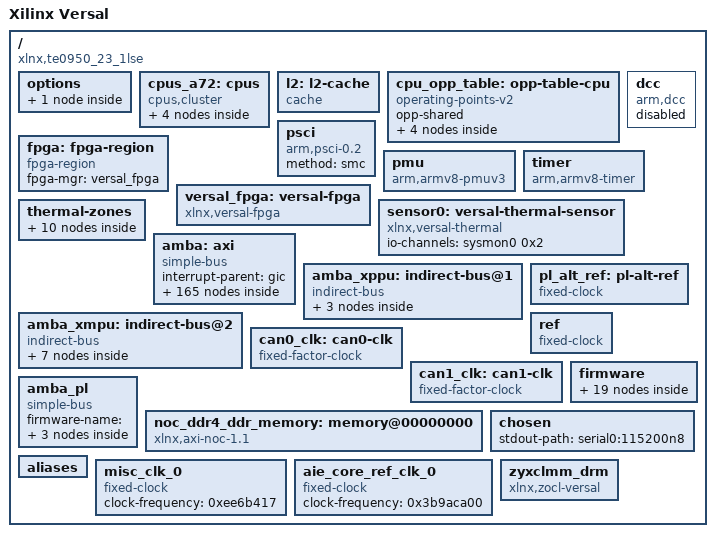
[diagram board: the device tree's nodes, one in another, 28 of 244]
/dts-v1/;
/ {
        compatible = "xlnx,te0950_23_1lse";
        #address-cells = <0x2>;
        #size-cells = <0x2>;
        model = "Xilinx Versal";
        board = "te0950_23_1lse";
        device_id = "xcve2302";
        slrcount = <0x1>;
        family = "Versal";
        speed_grade = "1LP";

        options {

                u-boot {
                        compatible = "u-boot,config";
                        bootscr-address = <0x0 0x20000000>;
                };
        };

        cpus_a72: cpus {
                phandle = <0xb8>;
                #address-cells = <0x1>;
                #size-cells = <0x0>;
                compatible = "cpus,cluster";
                #ranges-address-cells = <0x2>;
                #ranges-size-cells = <0x2>;

                psv_cortexa72_0: cpu@0 {
                        phandle = <0xb9>;
                        compatible = "arm,cortex-a72", "arm,armv8";
                        device_type = "cpu";
                        enable-method = "psci";
                        operating-points-v2 = <&cpu_opp_table>;
                        reg = <0x0>;
                        cpu-idle-states = <&CPU_SLEEP_0>;
                        power-domains = <&versal_firmware 0x18110003>;
                        d-cache-size = <0x8000>;
                        d-cache-line-size = <0x40>;
                        d-cache-sets = <0x100>;
                        i-cache-size = <0xc000>;
                        i-cache-line-size = <0x40>;
                        i-cache-sets = <0x100>;
                        next-level-cache = <&l2>;
                        clocks = <&versal_clk 0x4d>;
                        xlnx,timestamp-clk-freq = <0x5e0afa3>;
                        xlnx,pss-ref-clk-freq = <0x1fca055>;
                        stamp-frequency = <0x5e0afa3>;
                        xlnx,ip-name = "psv_cortexa72";
                        xlnx,cpu-clk-freq-hz = <0x391f0181>;
                        cpu-frequency = <0x391f0181>;
                        bus-handle = <0x1>;
                };

                psv_cortexa72_1: cpu@1 {
                        phandle = <0xba>;
                        compatible = "arm,cortex-a72", "arm,armv8";
                        device_type = "cpu";
                        enable-method = "psci";
                        operating-points-v2 = <&cpu_opp_table>;
                        reg = <0x1>;
                        cpu-idle-states = <&CPU_SLEEP_0>;
                        power-domains = <&versal_firmware 0x18110004>;
                        d-cache-size = <0x8000>;
                        d-cache-line-size = <0x40>;
                        d-cache-sets = <0x100>;
                        i-cache-size = <0xc000>;
                        i-cache-line-size = <0x40>;
                        i-cache-sets = <0x100>;
                        next-level-cache = <&l2>;
                        xlnx,timestamp-clk-freq = <0x5e0afa3>;
                        xlnx,pss-ref-clk-freq = <0x1fca055>;
                        stamp-frequency = <0x5e0afa3>;
                        xlnx,ip-name = "psv_cortexa72";
                        xlnx,cpu-clk-freq-hz = <0x391f0181>;
                        cpu-frequency = <0x391f0181>;
                        bus-handle = <0x1>;
                };

                idle-states {
                        entry-method = "psci";

                        CPU_SLEEP_0: cpu-sleep-0 {
                                phandle = <0x94>;
                                compatible = "arm,idle-state";
                                arm,psci-suspend-param = <0x40000000>;
                                local-timer-stop;
                                entry-latency-us = <0x12c>;
                                exit-latency-us = <0x258>;
                                min-residency-us = <0x2710>;
                        };
                };
        };

        l2: l2-cache {
                phandle = <0x96>;
                compatible = "cache";
                cache-level = <0x2>;
                cache-size = <0x100000>;
                cache-line-size = <0x40>;
                cache-sets = <0x1000>;
                cache-unified;
        };

        cpu_opp_table: opp-table-cpu {
                phandle = <0x93>;
                compatible = "operating-points-v2";
                opp-shared;

                opp-959000000 {
                        opp-hz = <0x0 0x39292dc0>;
                        clock-latency-ns = <0x7a120>;
                        opp-microvolt = <0xf4240>;
                };

                opp-479500000 {
                        opp-hz = <0x0 0x1c9496e0>;
                        clock-latency-ns = <0x7a120>;
                        opp-microvolt = <0xf4240>;
                };

                opp-319666667 {
                        opp-hz = <0x0 0x130db9eb>;
                        clock-latency-ns = <0x7a120>;
                        opp-microvolt = <0xf4240>;
                };

                opp-239750000 {
                        opp-hz = <0x0 0xe4a4b70>;
                        clock-latency-ns = <0x7a120>;
                        opp-microvolt = <0xf4240>;
                };
        };

        dcc: dcc {
                phandle = <0xc3>;
                compatible = "arm,dcc";
                status = "disabled";
                bootph-all;
        };

        fpga: fpga-region {
                phandle = <0xc4>;
                compatible = "fpga-region";
                fpga-mgr = <&versal_fpga>;
                #address-cells = <0x2>;
                #size-cells = <0x2>;
        };

        psci: psci {
                phandle = <0xc5>;
                compatible = "arm,psci-0.2";
                method = "smc";
        };

        pmu {
                compatible = "arm,armv8-pmuv3";
                interrupt-parent = <&gic>;
                interrupts = <0x1 0x7 0x304>;
        };

        timer: timer {
                phandle = <0xc6>;
                compatible = "arm,armv8-timer";
                interrupt-parent = <&gic>;
                interrupts = <0x1 0xd 0x4 0x1 0xe 0x4 0x1 0xb 0x4 0x1 0xa 0x4>;
        };

        versal_fpga: versal-fpga {
                phandle = <0xac>;
                compatible = "xlnx,versal-fpga";
        };

        sensor0: versal-thermal-sensor {
                phandle = <0xae>;
                compatible = "xlnx,versal-thermal";
                #thermal-sensor-cells = <0x1>;
                io-channels = <&sysmon0 0x2>;
                io-channel-names = "sysmon-temp-channel";
        };

        thermal-zones {

                versal_thermal: versal-thermal {
                        phandle = <0xc7>;
                        polling-delay-passive = <0xfa>;
                        polling-delay = <0x3e8>;
                        thermal-sensors = <&sensor0 0x0>;

                        trips {

                                temp_alert: temp-alert {
                                        phandle = <0xc8>;
                                        temperature = <0x11170>;
                                        hysteresis = <0x0>;
                                        type = "passive";
                                };

                                ot_crit: ot-crit {
                                        phandle = <0xc9>;
                                        temperature = <0x1e848>;
                                        hysteresis = <0x0>;
                                        type = "critical";
                                };
                        };

                        cooling-maps {
                        };
                };

                versal_thermal_aie: versal-aie-thermal {
                        phandle = <0xca>;
                        polling-delay-passive = <0xfa>;
                        polling-delay = <0x3e8>;
                        thermal-sensors = <&sensor0 0x1>;

                        trips {

                                temp_alert_aie: temp-alert-aie {
                                        phandle = <0xcb>;
                                        temperature = <0x11170>;
                                        hysteresis = <0x0>;
                                        type = "passive";
                                };

                                ot_crit_aie: ot-crit-aie {
                                        phandle = <0xcc>;
                                        temperature = <0x1e848>;
                                        hysteresis = <0x0>;
                                        type = "critical";
                                };
                        };

                        cooling-maps {
                        };
                };
        };

        amba: axi {
                phandle = <0x1>;
                compatible = "simple-bus";
                #address-cells = <0x2>;
                #size-cells = <0x2>;
                ranges;
                interrupt-parent = <&gic>;
                bootph-all;

                can0: can@ff060000 {
                        phandle = <0xcd>;
                        compatible = "xlnx,canfd-2.0";
                        status = "disabled";
                        reg = <0x0 0xff060000 0x0 0x6000>;
                        interrupts = <0x0 0x14 0x4>;
                        interrupt-parent = <&gic>;
                        clock-names = "can_clk", "s_axi_aclk";
                        rx-fifo-depth = <0x40>;
                        tx-mailbox-count = <0x20>;
                        clocks = <&can0_clk>,
                         <&versal_clk 0x52>;
                        power-domains = <&versal_firmware 0x1822401f>;
                };

                can1: can@ff070000 {
                        phandle = <0xce>;
                        compatible = "xlnx,canfd-2.0";
                        status = "disabled";
                        reg = <0x0 0xff070000 0x0 0x6000>;
                        interrupts = <0x0 0x15 0x4>;
                        interrupt-parent = <&gic>;
                        clock-names = "can_clk", "s_axi_aclk";
                        rx-fifo-depth = <0x40>;
                        tx-mailbox-count = <0x20>;
                        clocks = <&can1_clk>,
                         <&versal_clk 0x52>;
                        power-domains = <&versal_firmware 0x18224020>;
                };

                cci: cci@fd000000 {
                        phandle = <0x5d>;
                        compatible = "arm,cci-500";
                        status = "okay";
                        reg = <0x0 0xfd000000 0x0 0x10000>;
                        ranges = <0x0 0x0 0xfd000000 0xa0000>;
                        #address-cells = <0x1>;
                        #size-cells = <0x1>;
                        xlnx,ip-name = "psv_fpd_maincci";

                        cci_pmu: pmu@10000 {
                                phandle = <0xcf>;
                                compatible = "arm,cci-500-pmu,r0";
                                reg = <0x10000 0x90000>;
                                interrupt-parent = <&gic>;
                                interrupts = <0x0 0x6a 0x4 0x0 0x6a 0x4 0x0 0x6a 0x4 0x0 0x6a 0x4 0x0 0x6a 0x4 0x0 0x6a 0x4 0x0 0x6a 0x4 0x0 0x6a 0x4>;
                        };
                };

                lpd_dma_chan0: dma-controller@ffa80000 {
                        phandle = <0x86>;
                        compatible = "xlnx,zynqmp-dma-1.0";
                        status = "okay";
                        reg = <0x0 0xffa80000 0x0 0x1000>;
                        interrupts = <0x0 0x3c 0x4>;
                        interrupt-parent = <&gic>;
                        clock-names = "clk_main", "clk_apb";
                        xlnx,dma-type = <0x1>;
                        #dma-cells = <0x1>;
                        xlnx,bus-width = <0x40>;
                        clocks = <&versal_clk 0x51>,
                         <&versal_clk 0x52>;
                        power-domains = <&versal_firmware 0x18224035>;
                        xlnx,is-cache-coherent = <0x0>;
                        xlnx,ip-name = "psv_adma";
                        xlnx,dma-mode = <0x1>;
                };

                lpd_dma_chan1: dma-controller@ffa90000 {
                        phandle = <0x87>;
                        compatible = "xlnx,zynqmp-dma-1.0";
                        status = "okay";
                        reg = <0x0 0xffa90000 0x0 0x1000>;
                        interrupts = <0x0 0x3d 0x4>;
                        interrupt-parent = <&gic>;
                        clock-names = "clk_main", "clk_apb";
                        xlnx,dma-type = <0x1>;
                        #dma-cells = <0x1>;
                        xlnx,bus-width = <0x40>;
                        clocks = <&versal_clk 0x51>,
                         <&versal_clk 0x52>;
                        power-domains = <&versal_firmware 0x18224036>;
                        xlnx,is-cache-coherent = <0x0>;
                        xlnx,ip-name = "psv_adma";
                        xlnx,dma-mode = <0x1>;
                };

                lpd_dma_chan2: dma-controller@ffaa0000 {
                        phandle = <0x88>;
                        compatible = "xlnx,zynqmp-dma-1.0";
                        status = "okay";
                        reg = <0x0 0xffaa0000 0x0 0x1000>;
                        interrupts = <0x0 0x3e 0x4>;
                        interrupt-parent = <&gic>;
                        clock-names = "clk_main", "clk_apb";
                        xlnx,dma-type = <0x1>;
                        #dma-cells = <0x1>;
                        xlnx,bus-width = <0x40>;
                        clocks = <&versal_clk 0x51>,
                         <&versal_clk 0x52>;
                        power-domains = <&versal_firmware 0x18224037>;
                        xlnx,is-cache-coherent = <0x0>;
                        xlnx,ip-name = "psv_adma";
                        xlnx,dma-mode = <0x1>;
                };

                lpd_dma_chan3: dma-controller@ffab0000 {
                        phandle = <0x89>;
                        compatible = "xlnx,zynqmp-dma-1.0";
                        status = "okay";
                        reg = <0x0 0xffab0000 0x0 0x1000>;
                        interrupts = <0x0 0x3f 0x4>;
                        interrupt-parent = <&gic>;
                        clock-names = "clk_main", "clk_apb";
                        xlnx,dma-type = <0x1>;
                        #dma-cells = <0x1>;
                        xlnx,bus-width = <0x40>;
                        clocks = <&versal_clk 0x51>,
                         <&versal_clk 0x52>;
                        power-domains = <&versal_firmware 0x18224038>;
                        xlnx,is-cache-coherent = <0x0>;
                        xlnx,ip-name = "psv_adma";
                        xlnx,dma-mode = <0x1>;
                };

                lpd_dma_chan4: dma-controller@ffac0000 {
                        phandle = <0x8a>;
                        compatible = "xlnx,zynqmp-dma-1.0";
                        status = "okay";
                        reg = <0x0 0xffac0000 0x0 0x1000>;
                        interrupts = <0x0 0x40 0x4>;
                        interrupt-parent = <&gic>;
                        clock-names = "clk_main", "clk_apb";
                        xlnx,dma-type = <0x1>;
                        #dma-cells = <0x1>;
                        xlnx,bus-width = <0x40>;
                        clocks = <&versal_clk 0x51>,
                         <&versal_clk 0x52>;
                        power-domains = <&versal_firmware 0x18224039>;
                        xlnx,is-cache-coherent = <0x0>;
                        xlnx,ip-name = "psv_adma";
                        xlnx,dma-mode = <0x1>;
                };

                lpd_dma_chan5: dma-controller@ffad0000 {
                        phandle = <0x8b>;
                        compatible = "xlnx,zynqmp-dma-1.0";
                        status = "okay";
                        reg = <0x0 0xffad0000 0x0 0x1000>;
                        interrupts = <0x0 0x41 0x4>;
                        interrupt-parent = <&gic>;
                        clock-names = "clk_main", "clk_apb";
                        xlnx,dma-type = <0x1>;
                        #dma-cells = <0x1>;
                        xlnx,bus-width = <0x40>;
                        clocks = <&versal_clk 0x51>,
                         <&versal_clk 0x52>;
                        power-domains = <&versal_firmware 0x1822403a>;
                        xlnx,is-cache-coherent = <0x0>;
                        xlnx,ip-name = "psv_adma";
                        xlnx,dma-mode = <0x1>;
                };

                lpd_dma_chan6: dma-controller@ffae0000 {
                        phandle = <0x8c>;
                        compatible = "xlnx,zynqmp-dma-1.0";
                        status = "okay";
                        reg = <0x0 0xffae0000 0x0 0x1000>;
                        interrupts = <0x0 0x42 0x4>;
                        interrupt-parent = <&gic>;
                        clock-names = "clk_main", "clk_apb";
                        xlnx,dma-type = <0x1>;
                        #dma-cells = <0x1>;
                        xlnx,bus-width = <0x40>;
                        clocks = <&versal_clk 0x51>,
                         <&versal_clk 0x52>;
                        power-domains = <&versal_firmware 0x1822403b>;
                        xlnx,is-cache-coherent = <0x0>;
                        xlnx,ip-name = "psv_adma";
                        xlnx,dma-mode = <0x1>;
                };

                lpd_dma_chan7: dma-controller@ffaf0000 {
                        phandle = <0x8d>;
                        compatible = "xlnx,zynqmp-dma-1.0";
                        status = "okay";
                        reg = <0x0 0xffaf0000 0x0 0x1000>;
                        interrupts = <0x0 0x43 0x4>;
                        interrupt-parent = <&gic>;
                        clock-names = "clk_main", "clk_apb";
                        xlnx,dma-type = <0x1>;
                        #dma-cells = <0x1>;
                        xlnx,bus-width = <0x40>;
                        clocks = <&versal_clk 0x51>,
                         <&versal_clk 0x52>;
                        power-domains = <&versal_firmware 0x1822403c>;
                        xlnx,is-cache-coherent = <0x0>;
                        xlnx,ip-name = "psv_adma";
                        xlnx,dma-mode = <0x1>;
                };

                gem0: ethernet@ff0c0000 {
                        phandle = <0x6f>;
                        compatible = "xlnx,versal-gem", "cdns,gem";
                        status = "okay";
                        reg = <0x0 0xff0c0000 0x0 0x1000>;
                        interrupts = <0x0 0x38 0x4 0x0 0x38 0x4>;
                        interrupt-parent = <&gic>;
                        clock-names = "pclk", "hclk", "tx_clk", "rx_clk", "tsu_clk";
                        #address-cells = <0x1>;
                        #size-cells = <0x0>;
                        clocks = <&versal_clk 0x52>,
                         <&versal_clk 0x58>,
                         <&versal_clk 0x31>,
                         <&versal_clk 0x30>,
                         <&versal_clk 0x2b>;
                        power-domains = <&versal_firmware 0x18224019>;
                        xlnx,has-mdio = <0x1>;
                        xlnx,is-cache-coherent = <0x0>;
                        xlnx,gem-board-interface = "custom";
                        phy-mode = "rgmii-id";
                        xlnx,enet-slcr-1000mbps-div0 = <0x7>;
                        xlnx,enet-slcr-10mbps-div0 = <0x15e>;
                        xlnx,enet-tsu-clk-freq-hz = <0xe47c060>;
                        xlnx,ip-name = "psv_ethernet";
                        xlnx,eth-mode = <0x1>;
                        xlnx,enet-clk-freq-hz = <0x7735938>;
                        xlnx,enet-slcr-100mbps-div0 = <0x23>;
                };

                gem1: ethernet@ff0d0000 {
                        phandle = <0xd0>;
                        compatible = "xlnx,versal-gem", "cdns,gem";
                        status = "disabled";
                        reg = <0x0 0xff0d0000 0x0 0x1000>;
                        interrupts = <0x0 0x3a 0x4 0x0 0x3a 0x4>;
                        interrupt-parent = <&gic>;
                        clock-names = "pclk", "hclk", "tx_clk", "rx_clk", "tsu_clk";
                        #address-cells = <0x1>;
                        #size-cells = <0x0>;
                        clocks = <&versal_clk 0x52>,
                         <&versal_clk 0x59>,
                         <&versal_clk 0x33>,
                         <&versal_clk 0x32>,
                         <&versal_clk 0x2b>;
                        power-domains = <&versal_firmware 0x1822401a>;
                };

                gpio0: gpio@ff0b0000 {
                        phandle = <0x6e>;
                        compatible = "xlnx,versal-gpio-1.0";
                        status = "okay";
                        reg = <0x0 0xff0b0000 0x0 0x1000>;
                        interrupts = <0x0 0xd 0x4>;
                        interrupt-parent = <&gic>;
                        #gpio-cells = <0x2>;
                        gpio-controller;
                        #interrupt-cells = <0x2>;
                        interrupt-controller;
                        clocks = <&versal_clk 0x52>;
                        power-domains = <&versal_firmware 0x18224023>;
                        xlnx,ip-name = "psv_gpio";
                        emio-gpio-width = "";
                        gpio-line-names = "", "", "", "", "", "", "", "", "", "", "", "", "", "", "", "", "", "", "", "", "", "", "LPD_MIO22", "";
                };

                gpio1: gpio@f1020000 {
                        phandle = <0x31>;
                        compatible = "xlnx,pmc-gpio-1.0";
                        status = "okay";
                        reg = <0x0 0xf1020000 0x0 0x1000>;
                        interrupts = <0x0 0x7a 0x4>;
                        interrupt-parent = <&gic>;
                        #gpio-cells = <0x2>;
                        gpio-controller;
                        #interrupt-cells = <0x2>;
                        interrupt-controller;
                        clocks = <&versal_clk 0x3d>;
                        power-domains = <&versal_firmware 0x1822402c>;
                        xlnx,ip-name = "psv_pmc_gpio";
                        gpio-line-names = "", "", "", "", "", "", "", "", "", "", "", "", "", "", "", "", "", "", "", "", "", "", "", "", "", "", "", "PMC_MIO27", "", "", "", "", "", "", "", "", "", "USB_OC", "", "", "", "", "", "", "", "", "", "", "", "", "", "LED0", "", "", "", "", "", "", "", "";
                };

                i2c0: i2c@ff020000 {
                        phandle = <0xd1>;
                        compatible = "cdns,i2c-r1p14";
                        status = "disabled";
                        reg = <0x0 0xff020000 0x0 0x1000>;
                        interrupts = <0x0 0xe 0x4>;
                        interrupt-parent = <&gic>;
                        clock-frequency = <0x186a0>;
                        #address-cells = <0x1>;
                        #size-cells = <0x0>;
                        clocks = <&versal_clk 0x62>;
                        power-domains = <&versal_firmware 0x1822401d>;

                        i2cswitch@70 {
                                compatible = "nxp,pca9548";
                                #address-cells = <0x1>;
                                #size-cells = <0x0>;
                                reg = <0x70>;
                                i2c-mux-idle-disconnect;

                                i2c_cruvi_hs1: i2c@0 {
                                        phandle = <0xd2>;
                                        reg = <0x0>;
                                };

                                i2c_cruvi_hs2: i2c@1 {
                                        phandle = <0xd3>;
                                        reg = <0x1>;
                                };

                                i2c_qsfp: i2c@2 {
                                        phandle = <0xd4>;
                                        reg = <0x2>;
                                };

                                i2c_fmc: i2c@3 {
                                        phandle = <0xd5>;
                                        reg = <0x3>;
                                };
                        };
                };

                i2c1: i2c@ff030000 {
                        phandle = <0x6b>;
                        compatible = "cdns,i2c-r1p14";
                        status = "okay";
                        reg = <0x0 0xff030000 0x0 0x1000>;
                        interrupts = <0x0 0xf 0x4>;
                        interrupt-parent = <&gic>;
                        clock-frequency = <0x186a0>;
                        #address-cells = <0x1>;
                        #size-cells = <0x0>;
                        clocks = <&versal_clk 0x63>;
                        power-domains = <&versal_firmware 0x1822401e>;
                        xlnx,clock-freq = <0x5e0afa3>;
                        xlnx,i2c-clk-freq-hz = <0x5e0afa3>;
                        xlnx,ip-name = "psv_i2c";
                        xlnx,iic-board-interface = "custom";
                };

                i2c2: i2c@f1000000 {
                        phandle = <0x2f>;
                        compatible = "cdns,i2c-r1p14";
                        status = "okay";
                        reg = <0x0 0xf1000000 0x0 0x1000>;
                        interrupts = <0x0 0x7b 0x4>;
                        interrupt-parent = <&gic>;
                        clock-frequency = <0x186a0>;
                        #address-cells = <0x1>;
                        #size-cells = <0x0>;
                        clocks = <&versal_clk 0x3e>;
                        power-domains = <&versal_firmware 0x1822402d>;
                        xlnx,clock-freq = <0x5e0afa3>;
                        xlnx,i2c-clk-freq-hz = <0x5e0afa3>;
                        xlnx,ip-name = "psv_pmc_i2c";

                        eeprom: eeprom@50 {
                                phandle = <0xd6>;
                                compatible = "microchip,24aa025", "atmel,24c02";
                                reg = <0x50>;
                                #address-cells = <0x1>;
                                #size-cells = <0x1>;

                                eth0_addr: eth-mac-addr@FA {
                                        phandle = <0xd7>;
                                        reg = <0xfa 0x6>;
                                };
                        };
                };

                mc0: memory-controller@f6150000 {
                        phandle = <0xd8>;
                        compatible = "xlnx,versal-ddrmc";
                        status = "disabled";
                        reg = <0x0 0xf6150000 0x0 0x2000 0x0 0xf6070000 0x0 0x20000>;
                        reg-names = "base", "noc";
                        interrupts = <0x0 0x93 0x4>;
                        interrupt-parent = <&gic>;
                };

                mc1: memory-controller@f62c0000 {
                        phandle = <0xd9>;
                        compatible = "xlnx,versal-ddrmc";
                        status = "disabled";
                        reg = <0x0 0xf62c0000 0x0 0x2000 0x0 0xf6210000 0x0 0x20000>;
                        reg-names = "base", "noc";
                        interrupts = <0x0 0x93 0x4>;
                        interrupt-parent = <&gic>;
                };

                mc2: memory-controller@f6430000 {
                        phandle = <0xda>;
                        compatible = "xlnx,versal-ddrmc";
                        status = "disabled";
                        reg = <0x0 0xf6430000 0x0 0x2000 0x0 0xf6380000 0x0 0x20000>;
                        reg-names = "base", "noc";
                        interrupts = <0x0 0x93 0x4>;
                        interrupt-parent = <&gic>;
                };

                mc3: memory-controller@f65a0000 {
                        phandle = <0xdb>;
                        compatible = "xlnx,versal-ddrmc";
                        status = "disabled";
                        reg = <0x0 0xf65a0000 0x0 0x2000 0x0 0xf64f0000 0x0 0x20000>;
                        reg-names = "base", "noc";
                        interrupts = <0x0 0x93 0x4>;
                        interrupt-parent = <&gic>;
                };

                ocm: memory-controller@ff960000 {
                        phandle = <0xdc>;
                        compatible = "xlnx,zynqmp-ocmc-1.0";
                        reg = <0x0 0xff960000 0x0 0x1000>;
                        interrupts = <0x0 0xa 0x4>;
                        interrupt-parent = <&gic>;
                };

                rtc: rtc@f12a0000 {
                        phandle = <0x44>;
                        compatible = "xlnx,zynqmp-rtc";
                        status = "okay";
                        reg = <0x0 0xf12a0000 0x0 0x100>;
                        interrupt-names = "alarm", "sec";
                        interrupts = <0x0 0x8e 0x4 0x0 0x8f 0x4>;
                        interrupt-parent = <&gic>;
                        calibration = <0x7fff>;
                        power-domains = <&versal_firmware 0x18224034>;
                        xlnx,ip-name = "psv_pmc_rtc";
                };

                sdhci0: mmc@f1040000 {
                        phandle = <0x32>;
                        compatible = "xlnx,versal-8.9a", "arasan,sdhci-8.9a";
                        status = "okay";
                        reg = <0x0 0xf1040000 0x0 0x10000>;
                        interrupts = <0x0 0x7e 0x4>;
                        interrupt-parent = <&gic>;
                        clock-names = "clk_xin", "clk_ahb", "gate";
                        #clock-cells = <0x1>;
                        clock-output-names = "clk_out_sd0", "clk_in_sd0";
                        clocks = <&versal_clk 0x3b>,
                         <&versal_clk 0x52>,
                         <&versal_clk 0x4a>;
                        power-domains = <&versal_firmware 0x1822402e>;
                        xlnx,sd-board-interface = "custom";
                        xlnx,is-cache-coherent = <0x0>;
                        xlnx,clk-50-ddr-otap-dly = <0x5>;
                        xlnx,clk-50-sdr-itap-dly = <0x2c>;
                        xlnx,has-emio = <0x0>;
                        clock-frequency = <0xbc15f46>;
                        xlnx,clk-100-sdr-otap-dly = <0x0>;
                        xlnx,mio-bank = <0x1>;
                        xlnx,ip-name = "psv_pmc_sd";
                        xlnx,bus-width = <0x8>;
                        xlnx,card-detect = <0x0>;
                        xlnx,has-wp = <0x0>;
                        xlnx,has-cd = <0x0>;
                        xlnx,slot-type = <0x1>;
                        xlnx,clk-50-sdr-otap-dly = <0x5>;
                        xlnx,clk-50-ddr-itap-dly = <0x1e>;
                        xlnx,has-power = <0x0>;
                        xlnx,clk-200-sdr-otap-dly = <0x2>;
                        xlnx,sdio-clk-freq-hz = <0xbc15f46>;
                        xlnx,write-protect = <0x0>;
                        bus-width = <0x8>;
                };

                sdhci1: mmc@f1050000 {
                        phandle = <0x33>;
                        compatible = "xlnx,versal-8.9a", "arasan,sdhci-8.9a";
                        status = "okay";
                        reg = <0x0 0xf1050000 0x0 0x10000>;
                        interrupts = <0x0 0x80 0x4>;
                        interrupt-parent = <&gic>;
                        clock-names = "clk_xin", "clk_ahb", "gate";
                        #clock-cells = <0x1>;
                        clock-output-names = "clk_out_sd1", "clk_in_sd1";
                        clocks = <&versal_clk 0x3c>,
                         <&versal_clk 0x52>,
                         <&versal_clk 0x4a>;
                        power-domains = <&versal_firmware 0x1822402f>;
                        xlnx,sd-board-interface = "custom";
                        xlnx,is-cache-coherent = <0x0>;
                        xlnx,clk-50-ddr-otap-dly = <0x0>;
                        xlnx,clk-50-sdr-itap-dly = <0x2c>;
                        xlnx,has-emio = <0x0>;
                        clock-frequency = <0xbc15f46>;
                        xlnx,clk-100-sdr-otap-dly = <0x0>;
                        xlnx,mio-bank = <0x1>;
                        xlnx,ip-name = "psv_pmc_sd";
                        xlnx,bus-width = <0x4>;
                        xlnx,card-detect = <0x1>;
                        xlnx,has-wp = <0x0>;
                        xlnx,has-cd = <0x1>;
                        xlnx,slot-type = <0x2>;
                        xlnx,clk-50-sdr-otap-dly = <0x4>;
                        xlnx,clk-50-ddr-itap-dly = <0x0>;
                        xlnx,has-power = <0x0>;
                        xlnx,clk-200-sdr-otap-dly = <0x0>;
                        xlnx,sdio-clk-freq-hz = <0xbc15f46>;
                        xlnx,write-protect = <0x0>;
                        no-1-8-v;
                };

                serial0: serial@ff000000 {
                        phandle = <0xdd>;
                        compatible = "arm,pl011", "arm,primecell";
                        status = "disabled";
                        reg = <0x0 0xff000000 0x0 0x1000>;
                        interrupts = <0x0 0x12 0x4>;
                        interrupt-parent = <&gic>;
                        reg-io-width = <0x4>;
                        clock-names = "uartclk", "apb_pclk";
                        bootph-all;
                        clocks = <&versal_clk 0x5c>,
                         <&versal_clk 0x52>;
                        power-domains = <&versal_firmware 0x18224021>;
                };

                serial1: serial@ff010000 {
                        phandle = <0x6a>;
                        compatible = "arm,pl011", "arm,primecell";
                        status = "okay";
                        reg = <0x0 0xff010000 0x0 0x1000>;
                        interrupts = <0x0 0x13 0x4>;
                        interrupt-parent = <&gic>;
                        reg-io-width = <0x4>;
                        clock-names = "uartclk", "apb_pclk";
                        bootph-all;
                        clocks = <&versal_clk 0x5d>,
                         <&versal_clk 0x52>;
                        power-domains = <&versal_firmware 0x18224022>;
                        xlnx,clock-freq = <0x5e0afa3>;
                        u-boot,dm-pre-reloc;
                        xlnx,uart-board-interface = "custom";
                        xlnx,has-modem = <0x0>;
                        xlnx,ip-name = "psv_sbsauart";
                        xlnx,baudrate = <0x1c200>;
                        cts-override;
                        port-number = <0x0>;
                        xlnx,uart-clk-freq-hz = <0x5e0afa3>;
                };

                smmu: iommu@fd800000 {
                        phandle = <0x68>;
                        compatible = "arm,mmu-500";
                        status = "okay";
                        reg = <0x0 0xfd800000 0x0 0x40000>;
                        stream-match-mask = <0x7c00>;
                        #iommu-cells = <0x1>;
                        #global-interrupts = <0x1>;
                        interrupts = <0x0 0x6b 0x4 0x0 0x6b 0x4 0x0 0x6b 0x4 0x0 0x6b 0x4 0x0 0x6b 0x4 0x0 0x6b 0x4 0x0 0x6b 0x4 0x0 0x6b 0x4 0x0 0x6b 0x4 0x0 0x6b 0x4 0x0 0x6b 0x4 0x0 0x6b 0x4 0x0 0x6b 0x4 0x0 0x6b 0x4 0x0 0x6b 0x4 0x0 0x6b 0x4 0x0 0x6b 0x4 0x0 0x6b 0x4 0x0 0x6b 0x4 0x0 0x6b 0x4 0x0 0x6b 0x4 0x0 0x6b 0x4 0x0 0x6b 0x4 0x0 0x6b 0x4 0x0 0x6b 0x4 0x0 0x6b 0x4 0x0 0x6b 0x4 0x0 0x6b 0x4 0x0 0x6b 0x4 0x0 0x6b 0x4 0x0 0x6b 0x4 0x0 0x6b 0x4 0x0 0x6b 0x4>;
                        interrupt-parent = <&gic>;
                        xlnx,ip-name = "psv_fpd_smmutcu";
                };

                ospi: spi@f1010000 {
                        phandle = <0x30>;
                        compatible = "xlnx,versal-ospi-1.0", "cdns,qspi-nor";
                        status = "okay";
                        reg = <0x0 0xf1010000 0x0 0x10000 0x0 0xc0000000 0x0 0x20000000>;
                        interrupts = <0x0 0x7c 0x4>;
                        interrupt-parent = <&gic>;
                        cdns,fifo-depth = <0x100>;
                        cdns,fifo-width = <0x4>;
                        cdns,is-dma = <0x1>;
                        cdns,trigger-address = <0xc0000000>;
                        #address-cells = <0x1>;
                        #size-cells = <0x0>;
                        clocks = <&versal_clk 0x3a>;
                        power-domains = <&versal_firmware 0x1822402a>;
                        reset-names = "qspi";
                        resets = <&versal_reset 0xc10402e>;
                        is-stacked = <0x0>;
                        xlnx,is-cache-coherent = <0x0>;
                        xlnx,clock-freq = <0xbc15f46>;
                        xlnx,ip-name = "psv_pmc_ospi";
                        xlnx,ospi-clk-freq-hz = <0xbc15f46>;
                        is-dual = <0x0>;
                        xlnx,ospi-mode = <0x0>;
                };

                qspi: spi@f1030000 {
                        phandle = <0xde>;
                        compatible = "xlnx,versal-qspi-1.0";
                        status = "disabled";
                        reg = <0x0 0xf1030000 0x0 0x1000>;
                        interrupts = <0x0 0x7d 0x4>;
                        interrupt-parent = <&gic>;
                        clock-names = "ref_clk", "pclk";
                        #address-cells = <0x1>;
                        #size-cells = <0x0>;
                        clocks = <&versal_clk 0x39>,
                         <&versal_clk 0x52>;
                        power-domains = <&versal_firmware 0x1822402b>;
                        num-cs = <0x2>;

                        flash@0 {
                                compatible = "jedec,spi-nor";
                                reg = <0x0 0x1>;
                                parallel-memories = <0x0 0x8000000 0x0 0x8000000>;
                                spi-rx-bus-width = <0x4>;
                                spi-tx-bus-width = <0x4>;
                                spi-max-frequency = <0x2625a00>;
                                #address-cells = <0x1>;
                                #size-cells = <0x1>;
                        };
                };

                spi0: spi@ff040000 {
                        phandle = <0xdf>;
                        compatible = "cdns,spi-r1p6";
                        status = "disabled";
                        reg = <0x0 0xff040000 0x0 0x1000>;
                        interrupts = <0x0 0x10 0x4>;
                        interrupt-parent = <&gic>;
                        clock-names = "ref_clk", "pclk";
                        #address-cells = <0x1>;
                        #size-cells = <0x0>;
                        clocks = <&versal_clk 0x5e>,
                         <&versal_clk 0x52>;
                        power-domains = <&versal_firmware 0x1822401b>;
                };

                spi1: spi@ff050000 {
                        phandle = <0xe0>;
                        compatible = "cdns,spi-r1p6";
                        status = "disabled";
                        reg = <0x0 0xff050000 0x0 0x1000>;
                        interrupts = <0x0 0x11 0x4>;
                        interrupt-parent = <&gic>;
                        clock-names = "ref_clk", "pclk";
                        #address-cells = <0x1>;
                        #size-cells = <0x0>;
                        clocks = <&versal_clk 0x5f>,
                         <&versal_clk 0x52>;
                        power-domains = <&versal_firmware 0x1822401c>;
                };

                sysmon0: sysmon@f1270000 {
                        phandle = <0x43>;
                        compatible = "xlnx,versal-sysmon";
                        #io-channel-cells = <0x1>;
                        reg = <0x0 0xf1270000 0x0 0x4000>;
                        interrupts = <0x0 0x90 0x4>;
                        xlnx,numchannels = [02];
                        #address-cells = <0x2>;
                        #size-cells = <0x2>;
                        xlnx,nodeid = <0x18224055>;
                        xlnx,sat-1-desc = "PMC , system , ADC";
                        xlnx,sat-63-desc = "PS , FPD , satellite";
                        xlnx,sat-9-x = <0xae2>;
                        xlnx,sat-9-y = <0x2905>;
                        xlnx,meas-0-root-id = <0x0>;
                        xlnx,meas-1-root-id = <0x1>;
                        xlnx,ip-name = "psv_pmc_sysmon";
                        xlnx,sat-9-desc = "ME , satellite";
                        xlnx,sat-10-x = <0x319>;
                        xlnx,sat-10-y = <0x2905>;
                        xlnx,sat-2-x = <0x23>;
                        xlnx,sat-64-x = <0x23>;
                        xlnx,sat-13-desc = "Clocking , column , satellite";
                        xlnx,sat-2-y = <0xb34>;
                        xlnx,sat-64-y = <0xb34>;
                        xlnx,meas-0-aux-io-n = "LPD_MIO21_502";
                        xlnx,sat-6-desc = "VNOC , satellite";
                        xlnx,meas-0-aux-io-p = "LPD_MIO20_502";
                        xlnx,sat-6-x = <0x1a37>;
                        xlnx,sat-6-y = <0x19f9>;
                        xlnx,sat-10-desc = "ME , satellite";
                        xlnx,sat-3-desc = "XPIO , satellite";
                        xlnx,meas-1-aux-io-n = "LPD_MIO15_502";
                        xlnx,meas-0-slr-number = <0x0>;
                        xlnx,meas-1-aux-io-p = "LPD_MIO14_502";
                        xlnx,sat-11-x = <0xa0e>;
                        xlnx,sat-11-y = <0x23fc>;
                        xlnx,sat-3-x = <0x116a>;
                        status = "okay";
                        xlnx,sat-3-y = <0x5ff>;
                        xlnx,sat-8-desc = "ME , satellite";
                        xlnx,sat-7-x = <0x1a74>;
                        xlnx,sat-7-y = <0x2905>;
                        xlnx,sat-12-desc = "Clocking , column , satellite";
                        xlnx,sat-5-desc = "VNOC , satellite";
                        xlnx,sat-2-desc = "PMC , user , ADC";
                        xlnx,sat-64-desc = "PS , LPD , satellite";
                        xlnx,sat-12-x = <0xa0e>;
                        xlnx,sat-12-y = <0x1dc4>;
                        xlnx,sat-4-x = <0x1d4c>;
                        xlnx,sat-4-y = <0x5ff>;
                        xlnx,meas-1-slr-number = <0x0>;
                        xlnx,sat-8-x = <0x12ab>;
                        xlnx,sat-8-y = <0x2905>;
                        xlnx,meas-0 = "VAUX_CH0";
                        xlnx,meas-1 = "VAUX_CH1";
                        xlnx,sat-7-desc = "ME , satellite";
                        xlnx,sat-11-desc = "Clocking , column , satellite";
                        xlnx,sat-1-x = <0x23>;
                        xlnx,sat-63-x = <0x23>;
                        xlnx,sat-1-y = <0xb34>;
                        xlnx,sat-63-y = <0xb34>;
                        xlnx,sat-4-desc = "XPIO , satellite";
                        xlnx,sat-13-x = <0xa0e>;
                        xlnx,sat-13-y = <0x1795>;
                        xlnx,sat-5-x = <0x1a37>;
                        xlnx,sat-5-y = <0xe06>;

                        supply@0 {
                                reg = <0x0>;
                                xlnx,name = "vaux_ch0";
                        };

                        supply@1 {
                                reg = <0x1>;
                                xlnx,name = "vaux_ch1";
                        };
                };

                sysmon1: sysmon@109270000 {
                        phandle = <0xe1>;
                        compatible = "xlnx,versal-sysmon";
                        status = "disabled";
                        reg = <0x1 0x9270000 0x0 0x4000>;
                        xlnx,numchannels = [00];
                        #address-cells = <0x1>;
                        #size-cells = <0x0>;
                        xlnx,nodeid = <0x18225055>;
                };

                sysmon2: sysmon@111270000 {
                        phandle = <0xe2>;
                        compatible = "xlnx,versal-sysmon";
                        status = "disabled";
                        reg = <0x1 0x11270000 0x0 0x4000>;
                        xlnx,numchannels = [00];
                        #address-cells = <0x1>;
                        #size-cells = <0x0>;
                        xlnx,nodeid = <0x18226055>;
                };

                sysmon3: sysmon@119270000 {
                        phandle = <0xe3>;
                        compatible = "xlnx,versal-sysmon";
                        status = "disabled";
                        reg = <0x1 0x19270000 0x0 0x4000>;
                        xlnx,numchannels = [00];
                        #address-cells = <0x1>;
                        #size-cells = <0x0>;
                        xlnx,nodeid = <0x18227055>;
                };

                ttc0: timer@ff0e0000 {
                        phandle = <0xe4>;
                        compatible = "cdns,ttc";
                        status = "disabled";
                        interrupts = <0x0 0x25 0x4 0x0 0x26 0x4 0x0 0x27 0x4>;
                        interrupt-parent = <&gic>;
                        reg = <0x0 0xff0e0000 0x0 0x1000>;
                        timer-width = <0x20>;
                        clocks = <&versal_clk 0x27>;
                        power-domains = <&versal_firmware 0x18224024>;
                };

                ttc1: timer@ff0f0000 {
                        phandle = <0xe5>;
                        compatible = "cdns,ttc";
                        status = "disabled";
                        interrupts = <0x0 0x28 0x4 0x0 0x29 0x4 0x0 0x2a 0x4>;
                        interrupt-parent = <&gic>;
                        reg = <0x0 0xff0f0000 0x0 0x1000>;
                        timer-width = <0x20>;
                        clocks = <&versal_clk 0x28>;
                        power-domains = <&versal_firmware 0x18224025>;
                };

                ttc2: timer@ff100000 {
                        phandle = <0xe6>;
                        compatible = "cdns,ttc";
                        status = "disabled";
                        interrupts = <0x0 0x2b 0x4 0x0 0x2c 0x4 0x0 0x2d 0x4>;
                        interrupt-parent = <&gic>;
                        reg = <0x0 0xff100000 0x0 0x1000>;
                        timer-width = <0x20>;
                        clocks = <&versal_clk 0x29>;
                        power-domains = <&versal_firmware 0x18224026>;
                };

                ttc3: timer@ff110000 {
                        phandle = <0xe7>;
                        compatible = "cdns,ttc";
                        status = "disabled";
                        interrupts = <0x0 0x2e 0x4 0x0 0x2f 0x4 0x0 0x30 0x4>;
                        interrupt-parent = <&gic>;
                        reg = <0x0 0xff110000 0x0 0x1000>;
                        timer-width = <0x20>;
                        clocks = <&versal_clk 0x2a>;
                        power-domains = <&versal_firmware 0x18224027>;
                };

                usb0: usb@ff9d0000 {
                        phandle = <0x85>;
                        compatible = "xlnx,versal-dwc3";
                        status = "okay";
                        reg = <0x0 0xff9d0000 0x0 0x100>;
                        clock-names = "bus_clk", "ref_clk";
                        ranges;
                        #address-cells = <0x2>;
                        #size-cells = <0x2>;
                        clocks = <&versal_clk 0x5b>,
                         <&versal_clk 0x68>;
                        power-domains = <&versal_firmware 0x18224018>;
                        resets = <&versal_reset 0xc104036>;
                        xlnx,ip-name = "psv_usb";

                        dwc3_0: usb@fe200000 {
                                phandle = <0x69>;
                                compatible = "snps,dwc3";
                                status = "okay";
                                reg = <0x0 0xfe200000 0x0 0x10000>;
                                interrupt-names = "host", "peripheral", "otg", "wakeup";
                                interrupts = <0x0 0x16 0x4 0x0 0x16 0x4 0x0 0x1a 0x4 0x0 0x4a 0x4>;
                                interrupt-parent = <&gic>;
                                snps,dis_u2_susphy_quirk;
                                snps,dis_u3_susphy_quirk;
                                snps,quirk-frame-length-adjustment = <0x20>;
                                clock-names = "ref";
                                clocks = <&versal_clk 0x5b>;
                                xlnx,is-cache-coherent = <0x0>;
                                xlnx,ip-name = "psv_usb_xhci";
                                xlnx,enable-superspeed = <0x0>;
                                dr_mode = "host";
                        };
                };

                cpm_pciea: pci@fca10000 {
                        phandle = <0xe8>;
                        device_type = "pci";
                        #address-cells = <0x3>;
                        #interrupt-cells = <0x1>;
                        #size-cells = <0x2>;
                        compatible = "xlnx,versal-cpm-host-1.00";
                        status = "disabled";
                        interrupt-map = <0x0 0x0 0x0 0x1 &pcie_intc_0 0x0>,
                         <0x0 0x0 0x0 0x2 &pcie_intc_0 0x1>,
                         <0x0 0x0 0x0 0x3 &pcie_intc_0 0x2>,
                         <0x0 0x0 0x0 0x4 &pcie_intc_0 0x3>;
                        interrupt-map-mask = <0x0 0x0 0x0 0x7>;
                        interrupt-names = "misc";
                        interrupts = <0x0 0x48 0x4>;
                        xlnx,csr-slcr = <0x6 0x0>;
                        xlnx,num-of-bars = <0x2>;
                        xlnx,port-type = <0x1>;
                        interrupt-parent = <&gic>;
                        bus-range = <0x0 0xff>;
                        ranges = <0x2000000 0x0 0xe0010000 0x0 0xe0010000 0x0 0x10000000 0x43000000 0x80 0x0 0x80 0x0 0x0 0x80000000>;
                        msi-map = <0x0 &gic_its 0x0 0x10000>;
                        reg = <0x6 0x0 0x0 0x1000000 0x0 0xfca10000 0x0 0x1000 0x0 0xfca00000 0x0 0x10000>;
                        reg-names = "cfg", "cpm_slcr", "cpm_crx";

                        pcie_intc_0: interrupt-controller {
                                phandle = <0xb2>;
                                #address-cells = <0x0>;
                                #interrupt-cells = <0x1>;
                                interrupt-controller;
                        };
                };

                cpm5_pcie: pcie@fcdd0000 {
                        phandle = <0xe9>;
                        device_type = "pci";
                        #address-cells = <0x3>;
                        #interrupt-cells = <0x1>;
                        #size-cells = <0x2>;
                        compatible = "xlnx,versal-cpm5-host";
                        status = "disabled";
                        interrupt-map = <0x0 0x0 0x0 0x1 &pcie_intc_2 0x0>,
                         <0x0 0x0 0x0 0x2 &pcie_intc_2 0x1>,
                         <0x0 0x0 0x0 0x3 &pcie_intc_2 0x2>,
                         <0x0 0x0 0x0 0x4 &pcie_intc_2 0x3>;
                        interrupt-map-mask = <0x0 0x0 0x0 0x7>;
                        interrupt-names = "misc";
                        interrupts = <0x0 0x48 0x4>;
                        xlnx,csr-slcr = <0xfce20000>;
                        xlnx,num-of-bars = <0x2>;
                        xlnx,port-type = <0x1>;
                        interrupt-parent = <&gic>;
                        bus-range = <0x0 0xff>;
                        ranges = <0x2000000 0x0 0xe0000000 0x0 0xe0000000 0x0 0x10000000 0x43000000 0x80 0x0 0x80 0x0 0x0 0x80000000>;
                        msi-map = <0x0 &gic_its 0x0 0x10000>;
                        reg = <0x6 0x0 0x0 0x1000000 0x0 0xfcdd0000 0x0 0x1000 0x0 0xfce20000 0x0 0x10000 0x0 0xfcdc0000 0x0 0x10000>;
                        reg-names = "cfg", "cpm_slcr", "cpm_csr", "cpm_crx";

                        pcie_intc_2: interrupt-controller {
                                phandle = <0xb3>;
                                #address-cells = <0x0>;
                                #interrupt-cells = <0x1>;
                                interrupt-controller;
                        };
                };

                watchdog: watchdog@fd4d0000 {
                        phandle = <0xea>;
                        compatible = "xlnx,versal-wwdt";
                        status = "disabled";
                        reg = <0x0 0xfd4d0000 0x0 0x10000>;
                        interrupt-names = "wdt", "wwdt_reset_pending", "gwdt", "gwdt_reset_pending";
                        interrupts = <0x0 0x64 0x1 0x0 0x6d 0x1 0x0 0x6c 0x1 0x0 0x6e 0x1>;
                        interrupt-parent = <&gic>;
                        timeout-sec = <0x1e>;
                        clocks = <&versal_clk 0x4c>;
                        power-domains = <&versal_firmware 0x18224029>;
                };

                watchdog1: watchdog@ff120000 {
                        phandle = <0xeb>;
                        compatible = "xlnx,versal-wwdt";
                        status = "disabled";
                        reg = <0x0 0xff120000 0x0 0x10000>;
                        interrupt-parent = <&gic>;
                        interrupt-names = "wdt", "wwdt_reset_pending", "gwdt", "gwdt_reset_pending";
                        interrupts = <0x0 0x31 0x1 0x0 0x45 0x1 0x0 0x46 0x4 0x0 0x47 0x4>;
                        timeout-sec = <0x1e>;
                        clocks = <&versal_clk 0x52>;
                        power-domains = <&versal_firmware 0x18224028>;
                };

                xilsem_edac: edac@f2014050 {
                        phandle = <0xec>;
                        compatible = "xlnx,versal-xilsem-edac";
                        status = "disabled";
                        reg = <0x0 0xf2014050 0x0 0xc4>;
                };

                dma0: pmcdma@f11c0000 {
                        phandle = <0x38>;
                        status = "okay";
                        compatible = "xlnx,zynqmp-csudma-1.0";
                        interrupt-parent = <&gic>;
                        interrupts = <0x0 0x83 0x4>;
                        reg = <0x0 0xf11c0000 0x0 0x10000>;
                        xlnx,dma-type = <0x1>;
                        xlnx,ip-name = "psv_pmc_dma";
                };

                dma1: pmcdma@f11d0000 {
                        phandle = <0x39>;
                        status = "okay";
                        compatible = "xlnx,zynqmp-csudma-1.0";
                        interrupt-parent = <&gic>;
                        interrupts = <0x0 0x84 0x4>;
                        reg = <0x0 0xf11d0000 0x0 0x10000>;
                        xlnx,dma-type = <0x2>;
                        xlnx,ip-name = "psv_pmc_dma";
                };

                ipi0: mailbox@ff330000 {
                        phandle = <0x5>;
                        compatible = "xlnx,versal-ipi-mailbox";
                        interrupt-parent = <&gic>;
                        interrupts = <0x0 0x1e 0x4>;
                        reg = <0x0 0xff330000 0x0 0x10000 0x0 0xff3f0400 0x0 0x200>;
                        xlnx,ipi-id = <0x2>;
                        #address-cells = <0x2>;
                        #size-cells = <0x2>;
                        ranges;
                        reg-names = "ctrl", "msg";

                        ipi_0_to_ipi_0: child@ff330000 {
                                phandle = <0x10b>;
                                compatible = "xlnx,versal-ipi-dest-mailbox";
                                #mbox-cells = <0x1>;
                                xlnx,ipi-id = <0x2>;
                                reg = <0x0 0xff330000 0x0 0x10000 0x0 0xff3f0400 0x0 0x200>;
                                reg-names = "ctrl", "msg";
                        };

                        ipi_0_to_ipi_1: child@ff340000 {
                                phandle = <0x10c>;
                                compatible = "xlnx,versal-ipi-dest-mailbox";
                                #mbox-cells = <0x1>;
                                xlnx,ipi-id = <0x3>;
                                reg = <0x0 0xff340000 0x0 0x10000 0x0 0xff3f0600 0x0 0x200>;
                                reg-names = "ctrl", "msg";
                        };

                        ipi_0_to_ipi_2: child@ff350000 {
                                phandle = <0x10d>;
                                compatible = "xlnx,versal-ipi-dest-mailbox";
                                #mbox-cells = <0x1>;
                                xlnx,ipi-id = <0x4>;
                                reg = <0x0 0xff350000 0x0 0x10000 0x0 0xff3f0800 0x0 0x200>;
                                reg-names = "ctrl", "msg";
                        };

                        ipi_0_to_ipi_3: child@ff360000 {
                                phandle = <0x10e>;
                                compatible = "xlnx,versal-ipi-dest-mailbox";
                                #mbox-cells = <0x1>;
                                xlnx,ipi-id = <0x5>;
                                reg = <0x0 0xff360000 0x0 0x10000 0x0 0xff3f0a00 0x0 0x200>;
                                reg-names = "ctrl", "msg";
                        };

                        ipi_0_to_ipi_4: child@ff370000 {
                                phandle = <0x10f>;
                                compatible = "xlnx,versal-ipi-dest-mailbox";
                                #mbox-cells = <0x1>;
                                xlnx,ipi-id = <0x6>;
                                reg = <0x0 0xff370000 0x0 0x10000 0x0 0xff3f0c00 0x0 0x200>;
                                reg-names = "ctrl", "msg";
                        };

                        ipi_0_to_ipi_5: child@ff380000 {
                                phandle = <0x110>;
                                compatible = "xlnx,versal-ipi-dest-mailbox";
                                #mbox-cells = <0x1>;
                                xlnx,ipi-id = <0x7>;
                                reg = <0x0 0xff380000 0x0 0x10000 0x0 0xff3f0e00 0x0 0x200>;
                                reg-names = "ctrl", "msg";
                        };

                        ipi_0_to_ipi_6: child@ff3a0000 {
                                phandle = <0x111>;
                                compatible = "xlnx,versal-ipi-dest-mailbox";
                                #mbox-cells = <0x1>;
                                xlnx,ipi-id = <0x9>;
                                reg = <0x0 0xff3a0000 0x0 0x10000>;
                                reg-names = "ctrl";
                        };

                        ipi_0_to_ipi_pmc: child@ff320000 {
                                phandle = <0x112>;
                                compatible = "xlnx,versal-ipi-dest-mailbox";
                                #mbox-cells = <0x1>;
                                xlnx,ipi-id = <0x1>;
                                reg = <0x0 0xff320000 0x0 0x10000 0x0 0xff3f0200 0x0 0x200>;
                                reg-names = "ctrl", "msg";
                        };

                        ipi_0_to_ipi_pmc_nobuf: child@ff390000 {
                                phandle = <0x113>;
                                compatible = "xlnx,versal-ipi-dest-mailbox";
                                #mbox-cells = <0x1>;
                                xlnx,ipi-id = <0x8>;
                                reg = <0x0 0xff390000 0x0 0x10000>;
                                reg-names = "ctrl";
                        };

                        ipi_0_to_ipi_psm: child@ff310000 {
                                phandle = <0x114>;
                                compatible = "xlnx,versal-ipi-dest-mailbox";
                                #mbox-cells = <0x1>;
                                xlnx,ipi-id = <0x0>;
                                reg = <0x0 0xff310000 0x0 0x10000 0x0 0xff3f0000 0x0 0x200>;
                                reg-names = "ctrl", "msg";
                        };
                };

                ipi1: mailbox@ff340000 {
                        phandle = <0x6>;
                        compatible = "xlnx,versal-ipi-mailbox";
                        interrupt-parent = <&gic>;
                        interrupts = <0x0 0x1f 0x4>;
                        reg = <0x0 0xff340000 0x0 0x10000 0x0 0xff3f0600 0x0 0x200>;
                        xlnx,ipi-id = <0x3>;
                        #address-cells = <0x2>;
                        #size-cells = <0x2>;
                        ranges;
                        reg-names = "ctrl", "msg";

                        ipi_1_to_ipi_0: child@ff330000 {
                                phandle = <0x115>;
                                compatible = "xlnx,versal-ipi-dest-mailbox";
                                #mbox-cells = <0x1>;
                                xlnx,ipi-id = <0x2>;
                                reg = <0x0 0xff330000 0x0 0x10000 0x0 0xff3f0400 0x0 0x200>;
                                reg-names = "ctrl", "msg";
                        };

                        ipi_1_to_ipi_1: child@ff340000 {
                                phandle = <0x116>;
                                compatible = "xlnx,versal-ipi-dest-mailbox";
                                #mbox-cells = <0x1>;
                                xlnx,ipi-id = <0x3>;
                                reg = <0x0 0xff340000 0x0 0x10000 0x0 0xff3f0600 0x0 0x200>;
                                reg-names = "ctrl", "msg";
                        };

                        ipi_1_to_ipi_2: child@ff350000 {
                                phandle = <0x117>;
                                compatible = "xlnx,versal-ipi-dest-mailbox";
                                #mbox-cells = <0x1>;
                                xlnx,ipi-id = <0x4>;
                                reg = <0x0 0xff350000 0x0 0x10000 0x0 0xff3f0800 0x0 0x200>;
                                reg-names = "ctrl", "msg";
                        };

                        ipi_1_to_ipi_3: child@ff360000 {
                                phandle = <0x118>;
                                compatible = "xlnx,versal-ipi-dest-mailbox";
                                #mbox-cells = <0x1>;
                                xlnx,ipi-id = <0x5>;
                                reg = <0x0 0xff360000 0x0 0x10000 0x0 0xff3f0a00 0x0 0x200>;
                                reg-names = "ctrl", "msg";
                        };

                        ipi_1_to_ipi_4: child@ff370000 {
                                phandle = <0x119>;
                                compatible = "xlnx,versal-ipi-dest-mailbox";
                                #mbox-cells = <0x1>;
                                xlnx,ipi-id = <0x6>;
                                reg = <0x0 0xff370000 0x0 0x10000 0x0 0xff3f0c00 0x0 0x200>;
                                reg-names = "ctrl", "msg";
                        };

                        ipi_1_to_ipi_5: child@ff380000 {
                                phandle = <0x11a>;
                                compatible = "xlnx,versal-ipi-dest-mailbox";
                                #mbox-cells = <0x1>;
                                xlnx,ipi-id = <0x7>;
                                reg = <0x0 0xff380000 0x0 0x10000 0x0 0xff3f0e00 0x0 0x200>;
                                reg-names = "ctrl", "msg";
                        };

                        ipi_1_to_ipi_6: child@ff3a0000 {
                                phandle = <0x11b>;
                                compatible = "xlnx,versal-ipi-dest-mailbox";
                                #mbox-cells = <0x1>;
                                xlnx,ipi-id = <0x9>;
                                reg = <0x0 0xff3a0000 0x0 0x10000>;
                                reg-names = "ctrl";
                        };

                        ipi_1_to_ipi_pmc: child@ff320000 {
                                phandle = <0x11c>;
                                compatible = "xlnx,versal-ipi-dest-mailbox";
                                #mbox-cells = <0x1>;
                                xlnx,ipi-id = <0x1>;
                                reg = <0x0 0xff320000 0x0 0x10000 0x0 0xff3f0200 0x0 0x200>;
                                reg-names = "ctrl", "msg";
                        };

                        ipi_1_to_ipi_pmc_nobuf: child@ff390000 {
                                phandle = <0x11d>;
                                compatible = "xlnx,versal-ipi-dest-mailbox";
                                #mbox-cells = <0x1>;
                                xlnx,ipi-id = <0x8>;
                                reg = <0x0 0xff390000 0x0 0x10000>;
                                reg-names = "ctrl";
                        };

                        ipi_1_to_ipi_psm: child@ff310000 {
                                phandle = <0x11e>;
                                compatible = "xlnx,versal-ipi-dest-mailbox";
                                #mbox-cells = <0x1>;
                                xlnx,ipi-id = <0x0>;
                                reg = <0x0 0xff310000 0x0 0x10000 0x0 0xff3f0000 0x0 0x200>;
                                reg-names = "ctrl", "msg";
                        };
                };

                ipi2: mailbox@ff350000 {
                        phandle = <0x7>;
                        compatible = "xlnx,versal-ipi-mailbox";
                        interrupt-parent = <&gic>;
                        interrupts = <0x0 0x20 0x4>;
                        reg = <0x0 0xff350000 0x0 0x10000 0x0 0xff3f0800 0x0 0x200>;
                        xlnx,ipi-id = <0x4>;
                        #address-cells = <0x2>;
                        #size-cells = <0x2>;
                        ranges;
                        reg-names = "ctrl", "msg";

                        ipi_2_to_ipi_0: child@ff330000 {
                                phandle = <0x11f>;
                                compatible = "xlnx,versal-ipi-dest-mailbox";
                                #mbox-cells = <0x1>;
                                xlnx,ipi-id = <0x2>;
                                reg = <0x0 0xff330000 0x0 0x10000 0x0 0xff3f0400 0x0 0x200>;
                                reg-names = "ctrl", "msg";
                        };

                        ipi_2_to_ipi_1: child@ff340000 {
                                phandle = <0x120>;
                                compatible = "xlnx,versal-ipi-dest-mailbox";
                                #mbox-cells = <0x1>;
                                xlnx,ipi-id = <0x3>;
                                reg = <0x0 0xff340000 0x0 0x10000 0x0 0xff3f0600 0x0 0x200>;
                                reg-names = "ctrl", "msg";
                        };

                        ipi_2_to_ipi_2: child@ff350000 {
                                phandle = <0x121>;
                                compatible = "xlnx,versal-ipi-dest-mailbox";
                                #mbox-cells = <0x1>;
                                xlnx,ipi-id = <0x4>;
                                reg = <0x0 0xff350000 0x0 0x10000 0x0 0xff3f0800 0x0 0x200>;
                                reg-names = "ctrl", "msg";
                        };

                        ipi_2_to_ipi_3: child@ff360000 {
                                phandle = <0x122>;
                                compatible = "xlnx,versal-ipi-dest-mailbox";
                                #mbox-cells = <0x1>;
                                xlnx,ipi-id = <0x5>;
                                reg = <0x0 0xff360000 0x0 0x10000 0x0 0xff3f0a00 0x0 0x200>;
                                reg-names = "ctrl", "msg";
                        };

                        ipi_2_to_ipi_4: child@ff370000 {
                                phandle = <0x123>;
                                compatible = "xlnx,versal-ipi-dest-mailbox";
                                #mbox-cells = <0x1>;
                                xlnx,ipi-id = <0x6>;
                                reg = <0x0 0xff370000 0x0 0x10000 0x0 0xff3f0c00 0x0 0x200>;
                                reg-names = "ctrl", "msg";
                        };

                        ipi_2_to_ipi_5: child@ff380000 {
                                phandle = <0x124>;
                                compatible = "xlnx,versal-ipi-dest-mailbox";
                                #mbox-cells = <0x1>;
                                xlnx,ipi-id = <0x7>;
                                reg = <0x0 0xff380000 0x0 0x10000 0x0 0xff3f0e00 0x0 0x200>;
                                reg-names = "ctrl", "msg";
                        };

                        ipi_2_to_ipi_6: child@ff3a0000 {
                                phandle = <0x125>;
                                compatible = "xlnx,versal-ipi-dest-mailbox";
                                #mbox-cells = <0x1>;
                                xlnx,ipi-id = <0x9>;
                                reg = <0x0 0xff3a0000 0x0 0x10000>;
                                reg-names = "ctrl";
                        };

                        ipi_2_to_ipi_pmc: child@ff320000 {
                                phandle = <0x126>;
                                compatible = "xlnx,versal-ipi-dest-mailbox";
                                #mbox-cells = <0x1>;
                                xlnx,ipi-id = <0x1>;
                                reg = <0x0 0xff320000 0x0 0x10000 0x0 0xff3f0200 0x0 0x200>;
                                reg-names = "ctrl", "msg";
                        };

                        ipi_2_to_ipi_pmc_nobuf: child@ff390000 {
                                phandle = <0x127>;
                                compatible = "xlnx,versal-ipi-dest-mailbox";
                                #mbox-cells = <0x1>;
                                xlnx,ipi-id = <0x8>;
                                reg = <0x0 0xff390000 0x0 0x10000>;
                                reg-names = "ctrl";
                        };

                        ipi_2_to_ipi_psm: child@ff310000 {
                                phandle = <0x128>;
                                compatible = "xlnx,versal-ipi-dest-mailbox";
                                #mbox-cells = <0x1>;
                                xlnx,ipi-id = <0x0>;
                                reg = <0x0 0xff310000 0x0 0x10000 0x0 0xff3f0000 0x0 0x200>;
                                reg-names = "ctrl", "msg";
                        };
                };

                ipi3: mailbox@ff360000 {
                        phandle = <0x8>;
                        compatible = "xlnx,versal-ipi-mailbox";
                        interrupt-parent = <&gic>;
                        interrupts = <0x0 0x21 0x4>;
                        reg = <0x0 0xff360000 0x0 0x10000 0x0 0xff3f0a00 0x0 0x200>;
                        xlnx,ipi-id = <0x5>;
                        #address-cells = <0x2>;
                        #size-cells = <0x2>;
                        ranges;
                        reg-names = "ctrl", "msg";

                        ipi_3_to_ipi_0: child@ff330000 {
                                phandle = <0x129>;
                                compatible = "xlnx,versal-ipi-dest-mailbox";
                                #mbox-cells = <0x1>;
                                xlnx,ipi-id = <0x2>;
                                reg = <0x0 0xff330000 0x0 0x10000 0x0 0xff3f0400 0x0 0x200>;
                                reg-names = "ctrl", "msg";
                        };

                        ipi_3_to_ipi_1: child@ff340000 {
                                phandle = <0x12a>;
                                compatible = "xlnx,versal-ipi-dest-mailbox";
                                #mbox-cells = <0x1>;
                                xlnx,ipi-id = <0x3>;
                                reg = <0x0 0xff340000 0x0 0x10000 0x0 0xff3f0600 0x0 0x200>;
                                reg-names = "ctrl", "msg";
                        };

                        ipi_3_to_ipi_2: child@ff350000 {
                                phandle = <0x12b>;
                                compatible = "xlnx,versal-ipi-dest-mailbox";
                                #mbox-cells = <0x1>;
                                xlnx,ipi-id = <0x4>;
                                reg = <0x0 0xff350000 0x0 0x10000 0x0 0xff3f0800 0x0 0x200>;
                                reg-names = "ctrl", "msg";
                        };

                        ipi_3_to_ipi_3: child@ff360000 {
                                phandle = <0x12c>;
                                compatible = "xlnx,versal-ipi-dest-mailbox";
                                #mbox-cells = <0x1>;
                                xlnx,ipi-id = <0x5>;
                                reg = <0x0 0xff360000 0x0 0x10000 0x0 0xff3f0a00 0x0 0x200>;
                                reg-names = "ctrl", "msg";
                        };

                        ipi_3_to_ipi_4: child@ff370000 {
                                phandle = <0x12d>;
                                compatible = "xlnx,versal-ipi-dest-mailbox";
                                #mbox-cells = <0x1>;
                                xlnx,ipi-id = <0x6>;
                                reg = <0x0 0xff370000 0x0 0x10000 0x0 0xff3f0c00 0x0 0x200>;
                                reg-names = "ctrl", "msg";
                        };

                        ipi_3_to_ipi_5: child@ff380000 {
                                phandle = <0x12e>;
                                compatible = "xlnx,versal-ipi-dest-mailbox";
                                #mbox-cells = <0x1>;
                                xlnx,ipi-id = <0x7>;
                                reg = <0x0 0xff380000 0x0 0x10000 0x0 0xff3f0e00 0x0 0x200>;
                                reg-names = "ctrl", "msg";
                        };

                        ipi_3_to_ipi_6: child@ff3a0000 {
                                phandle = <0x12f>;
                                compatible = "xlnx,versal-ipi-dest-mailbox";
                                #mbox-cells = <0x1>;
                                xlnx,ipi-id = <0x9>;
                                reg = <0x0 0xff3a0000 0x0 0x10000>;
                                reg-names = "ctrl";
                        };

                        ipi_3_to_ipi_pmc: child@ff320000 {
                                phandle = <0x130>;
                                compatible = "xlnx,versal-ipi-dest-mailbox";
                                #mbox-cells = <0x1>;
                                xlnx,ipi-id = <0x1>;
                                reg = <0x0 0xff320000 0x0 0x10000 0x0 0xff3f0200 0x0 0x200>;
                                reg-names = "ctrl", "msg";
                        };

                        ipi_3_to_ipi_pmc_nobuf: child@ff390000 {
                                phandle = <0x131>;
                                compatible = "xlnx,versal-ipi-dest-mailbox";
                                #mbox-cells = <0x1>;
                                xlnx,ipi-id = <0x8>;
                                reg = <0x0 0xff390000 0x0 0x10000>;
                                reg-names = "ctrl";
                        };

                        ipi_3_to_ipi_psm: child@ff310000 {
                                phandle = <0x132>;
                                compatible = "xlnx,versal-ipi-dest-mailbox";
                                #mbox-cells = <0x1>;
                                xlnx,ipi-id = <0x0>;
                                reg = <0x0 0xff310000 0x0 0x10000 0x0 0xff3f0000 0x0 0x200>;
                                reg-names = "ctrl", "msg";
                        };
                };

                ipi4: mailbox@ff370000 {
                        phandle = <0x9>;
                        compatible = "xlnx,versal-ipi-mailbox";
                        interrupt-parent = <&gic>;
                        interrupts = <0x0 0x22 0x4>;
                        reg = <0x0 0xff370000 0x0 0x10000 0x0 0xff3f0c00 0x0 0x200>;
                        xlnx,ipi-id = <0x6>;
                        #address-cells = <0x2>;
                        #size-cells = <0x2>;
                        ranges;
                        reg-names = "ctrl", "msg";

                        ipi_4_to_ipi_0: child@ff330000 {
                                phandle = <0x133>;
                                compatible = "xlnx,versal-ipi-dest-mailbox";
                                #mbox-cells = <0x1>;
                                xlnx,ipi-id = <0x2>;
                                reg = <0x0 0xff330000 0x0 0x10000 0x0 0xff3f0400 0x0 0x200>;
                                reg-names = "ctrl", "msg";
                        };

                        ipi_4_to_ipi_1: child@ff340000 {
                                phandle = <0x134>;
                                compatible = "xlnx,versal-ipi-dest-mailbox";
                                #mbox-cells = <0x1>;
                                xlnx,ipi-id = <0x3>;
                                reg = <0x0 0xff340000 0x0 0x10000 0x0 0xff3f0600 0x0 0x200>;
                                reg-names = "ctrl", "msg";
                        };

                        ipi_4_to_ipi_2: child@ff350000 {
                                phandle = <0x135>;
                                compatible = "xlnx,versal-ipi-dest-mailbox";
                                #mbox-cells = <0x1>;
                                xlnx,ipi-id = <0x4>;
                                reg = <0x0 0xff350000 0x0 0x10000 0x0 0xff3f0800 0x0 0x200>;
                                reg-names = "ctrl", "msg";
                        };

                        ipi_4_to_ipi_3: child@ff360000 {
                                phandle = <0x136>;
                                compatible = "xlnx,versal-ipi-dest-mailbox";
                                #mbox-cells = <0x1>;
                                xlnx,ipi-id = <0x5>;
                                reg = <0x0 0xff360000 0x0 0x10000 0x0 0xff3f0a00 0x0 0x200>;
                                reg-names = "ctrl", "msg";
                        };

                        ipi_4_to_ipi_4: child@ff370000 {
                                phandle = <0x137>;
                                compatible = "xlnx,versal-ipi-dest-mailbox";
                                #mbox-cells = <0x1>;
                                xlnx,ipi-id = <0x6>;
                                reg = <0x0 0xff370000 0x0 0x10000 0x0 0xff3f0c00 0x0 0x200>;
                                reg-names = "ctrl", "msg";
                        };

                        ipi_4_to_ipi_5: child@ff380000 {
                                phandle = <0x138>;
                                compatible = "xlnx,versal-ipi-dest-mailbox";
                                #mbox-cells = <0x1>;
                                xlnx,ipi-id = <0x7>;
                                reg = <0x0 0xff380000 0x0 0x10000 0x0 0xff3f0e00 0x0 0x200>;
                                reg-names = "ctrl", "msg";
                        };

                        ipi_4_to_ipi_6: child@ff3a0000 {
                                phandle = <0x139>;
                                compatible = "xlnx,versal-ipi-dest-mailbox";
                                #mbox-cells = <0x1>;
                                xlnx,ipi-id = <0x9>;
                                reg = <0x0 0xff3a0000 0x0 0x10000>;
                                reg-names = "ctrl";
                        };

                        ipi_4_to_ipi_pmc: child@ff320000 {
                                phandle = <0x13a>;
                                compatible = "xlnx,versal-ipi-dest-mailbox";
                                #mbox-cells = <0x1>;
                                xlnx,ipi-id = <0x1>;
                                reg = <0x0 0xff320000 0x0 0x10000 0x0 0xff3f0200 0x0 0x200>;
                                reg-names = "ctrl", "msg";
                        };

                        ipi_4_to_ipi_pmc_nobuf: child@ff390000 {
                                phandle = <0x13b>;
                                compatible = "xlnx,versal-ipi-dest-mailbox";
                                #mbox-cells = <0x1>;
                                xlnx,ipi-id = <0x8>;
                                reg = <0x0 0xff390000 0x0 0x10000>;
                                reg-names = "ctrl";
                        };

                        ipi_4_to_ipi_psm: child@ff310000 {
                                phandle = <0x13c>;
                                compatible = "xlnx,versal-ipi-dest-mailbox";
                                #mbox-cells = <0x1>;
                                xlnx,ipi-id = <0x0>;
                                reg = <0x0 0xff310000 0x0 0x10000 0x0 0xff3f0000 0x0 0x200>;
                                reg-names = "ctrl", "msg";
                        };
                };

                ipi5: mailbox@ff380000 {
                        phandle = <0xa>;
                        compatible = "xlnx,versal-ipi-mailbox";
                        interrupt-parent = <&gic>;
                        interrupts = <0x0 0x23 0x4>;
                        reg = <0x0 0xff380000 0x0 0x10000 0x0 0xff3f0e00 0x0 0x200>;
                        xlnx,ipi-id = <0x7>;
                        #address-cells = <0x2>;
                        #size-cells = <0x2>;
                        ranges;
                        reg-names = "ctrl", "msg";

                        ipi_5_to_ipi_0: child@ff330000 {
                                phandle = <0x13d>;
                                compatible = "xlnx,versal-ipi-dest-mailbox";
                                #mbox-cells = <0x1>;
                                xlnx,ipi-id = <0x2>;
                                reg = <0x0 0xff330000 0x0 0x10000 0x0 0xff3f0400 0x0 0x200>;
                                reg-names = "ctrl", "msg";
                        };

                        ipi_5_to_ipi_1: child@ff340000 {
                                phandle = <0x13e>;
                                compatible = "xlnx,versal-ipi-dest-mailbox";
                                #mbox-cells = <0x1>;
                                xlnx,ipi-id = <0x3>;
                                reg = <0x0 0xff340000 0x0 0x10000 0x0 0xff3f0600 0x0 0x200>;
                                reg-names = "ctrl", "msg";
                        };

                        ipi_5_to_ipi_2: child@ff350000 {
                                phandle = <0x13f>;
                                compatible = "xlnx,versal-ipi-dest-mailbox";
                                #mbox-cells = <0x1>;
                                xlnx,ipi-id = <0x4>;
                                reg = <0x0 0xff350000 0x0 0x10000 0x0 0xff3f0800 0x0 0x200>;
                                reg-names = "ctrl", "msg";
                        };

                        ipi_5_to_ipi_3: child@ff360000 {
                                phandle = <0x140>;
                                compatible = "xlnx,versal-ipi-dest-mailbox";
                                #mbox-cells = <0x1>;
                                xlnx,ipi-id = <0x5>;
                                reg = <0x0 0xff360000 0x0 0x10000 0x0 0xff3f0a00 0x0 0x200>;
                                reg-names = "ctrl", "msg";
                        };

                        ipi_5_to_ipi_4: child@ff370000 {
                                phandle = <0x141>;
                                compatible = "xlnx,versal-ipi-dest-mailbox";
                                #mbox-cells = <0x1>;
                                xlnx,ipi-id = <0x6>;
                                reg = <0x0 0xff370000 0x0 0x10000 0x0 0xff3f0c00 0x0 0x200>;
                                reg-names = "ctrl", "msg";
                        };

                        ipi_5_to_ipi_5: child@ff380000 {
                                phandle = <0x142>;
                                compatible = "xlnx,versal-ipi-dest-mailbox";
                                #mbox-cells = <0x1>;
                                xlnx,ipi-id = <0x7>;
                                reg = <0x0 0xff380000 0x0 0x10000 0x0 0xff3f0e00 0x0 0x200>;
                                reg-names = "ctrl", "msg";
                        };

                        ipi_5_to_ipi_6: child@ff3a0000 {
                                phandle = <0x143>;
                                compatible = "xlnx,versal-ipi-dest-mailbox";
                                #mbox-cells = <0x1>;
                                xlnx,ipi-id = <0x9>;
                                reg = <0x0 0xff3a0000 0x0 0x10000>;
                                reg-names = "ctrl";
                        };

                        ipi_5_to_ipi_pmc: child@ff320000 {
                                phandle = <0x144>;
                                compatible = "xlnx,versal-ipi-dest-mailbox";
                                #mbox-cells = <0x1>;
                                xlnx,ipi-id = <0x1>;
                                reg = <0x0 0xff320000 0x0 0x10000 0x0 0xff3f0200 0x0 0x200>;
                                reg-names = "ctrl", "msg";
                        };

                        ipi_5_to_ipi_pmc_nobuf: child@ff390000 {
                                phandle = <0x145>;
                                compatible = "xlnx,versal-ipi-dest-mailbox";
                                #mbox-cells = <0x1>;
                                xlnx,ipi-id = <0x8>;
                                reg = <0x0 0xff390000 0x0 0x10000>;
                                reg-names = "ctrl";
                        };

                        ipi_5_to_ipi_psm: child@ff310000 {
                                phandle = <0x146>;
                                compatible = "xlnx,versal-ipi-dest-mailbox";
                                #mbox-cells = <0x1>;
                                xlnx,ipi-id = <0x0>;
                                reg = <0x0 0xff310000 0x0 0x10000 0x0 0xff3f0000 0x0 0x200>;
                                reg-names = "ctrl", "msg";
                        };
                };

                ipi6: mailbox@ff3a0000 {
                        phandle = <0xb>;
                        compatible = "xlnx,versal-ipi-mailbox";
                        interrupt-parent = <&gic>;
                        interrupts = <0x0 0x24 0x4>;
                        reg = <0x0 0xff3a0000 0x0 0x10000>;
                        xlnx,ipi-id = <0x9>;
                        #address-cells = <0x2>;
                        #size-cells = <0x2>;
                        ranges;
                        reg-names = "ctrl";

                        ipi_6_to_ipi_0: child@ff330000 {
                                phandle = <0x147>;
                                compatible = "xlnx,versal-ipi-dest-mailbox";
                                #mbox-cells = <0x1>;
                                xlnx,ipi-id = <0x2>;
                                reg = <0x0 0xff330000 0x0 0x10000 0x0 0xff3f0400 0x0 0x200>;
                                reg-names = "ctrl", "msg";
                        };

                        ipi_6_to_ipi_1: child@ff340000 {
                                phandle = <0x148>;
                                compatible = "xlnx,versal-ipi-dest-mailbox";
                                #mbox-cells = <0x1>;
                                xlnx,ipi-id = <0x3>;
                                reg = <0x0 0xff340000 0x0 0x10000 0x0 0xff3f0600 0x0 0x200>;
                                reg-names = "ctrl", "msg";
                        };

                        ipi_6_to_ipi_2: child@ff350000 {
                                phandle = <0x149>;
                                compatible = "xlnx,versal-ipi-dest-mailbox";
                                #mbox-cells = <0x1>;
                                xlnx,ipi-id = <0x4>;
                                reg = <0x0 0xff350000 0x0 0x10000 0x0 0xff3f0800 0x0 0x200>;
                                reg-names = "ctrl", "msg";
                        };

                        ipi_6_to_ipi_3: child@ff360000 {
                                phandle = <0x14a>;
                                compatible = "xlnx,versal-ipi-dest-mailbox";
                                #mbox-cells = <0x1>;
                                xlnx,ipi-id = <0x5>;
                                reg = <0x0 0xff360000 0x0 0x10000 0x0 0xff3f0a00 0x0 0x200>;
                                reg-names = "ctrl", "msg";
                        };

                        ipi_6_to_ipi_4: child@ff370000 {
                                phandle = <0x14b>;
                                compatible = "xlnx,versal-ipi-dest-mailbox";
                                #mbox-cells = <0x1>;
                                xlnx,ipi-id = <0x6>;
                                reg = <0x0 0xff370000 0x0 0x10000 0x0 0xff3f0c00 0x0 0x200>;
                                reg-names = "ctrl", "msg";
                        };

                        ipi_6_to_ipi_5: child@ff380000 {
                                phandle = <0x14c>;
                                compatible = "xlnx,versal-ipi-dest-mailbox";
                                #mbox-cells = <0x1>;
                                xlnx,ipi-id = <0x7>;
                                reg = <0x0 0xff380000 0x0 0x10000 0x0 0xff3f0e00 0x0 0x200>;
                                reg-names = "ctrl", "msg";
                        };

                        ipi_6_to_ipi_6: child@ff3a0000 {
                                phandle = <0x14d>;
                                compatible = "xlnx,versal-ipi-dest-mailbox";
                                #mbox-cells = <0x1>;
                                xlnx,ipi-id = <0x9>;
                                reg = <0x0 0xff3a0000 0x0 0x10000>;
                                reg-names = "ctrl";
                        };

                        ipi_6_to_ipi_pmc: child@ff320000 {
                                phandle = <0x14e>;
                                compatible = "xlnx,versal-ipi-dest-mailbox";
                                #mbox-cells = <0x1>;
                                xlnx,ipi-id = <0x1>;
                                reg = <0x0 0xff320000 0x0 0x10000 0x0 0xff3f0200 0x0 0x200>;
                                reg-names = "ctrl", "msg";
                        };

                        ipi_6_to_ipi_pmc_nobuf: child@ff390000 {
                                phandle = <0x14f>;
                                compatible = "xlnx,versal-ipi-dest-mailbox";
                                #mbox-cells = <0x1>;
                                xlnx,ipi-id = <0x8>;
                                reg = <0x0 0xff390000 0x0 0x10000>;
                                reg-names = "ctrl";
                        };

                        ipi_6_to_ipi_psm: child@ff310000 {
                                phandle = <0x150>;
                                compatible = "xlnx,versal-ipi-dest-mailbox";
                                #mbox-cells = <0x1>;
                                xlnx,ipi-id = <0x0>;
                                reg = <0x0 0xff310000 0x0 0x10000 0x0 0xff3f0000 0x0 0x200>;
                                reg-names = "ctrl", "msg";
                        };
                };

                coresight: coresight@f0800000 {
                        phandle = <0xf>;
                        compatible = "xlnx,coresight-1.0";
                        status = "okay";
                        reg = <0x0 0xf0800000 0x0 0x10000>;
                        xlnx,ip-name = "psv_coresight";
                };

                CIPS_0_pspmc_0_psv_coresight_fpd_cti1b: CIPS_0_pspmc_0_psv_coresight_fpd_cti1b@f0bb0000 {
                        phandle = <0x17>;
                        compatible = "xlnx,psv-coresight-fpd-cti1b-1.0";
                        status = "okay";
                        xlnx,ip-name = "psv_coresight_fpd_cti1b";
                        reg = <0x0 0xf0bb0000 0x0 0x10000>;
                };

                CIPS_0_pspmc_0_psv_coresight_fpd_cti1c: CIPS_0_pspmc_0_psv_coresight_fpd_cti1c@f0bc0000 {
                        phandle = <0x18>;
                        compatible = "xlnx,psv-coresight-fpd-cti1c-1.0";
                        status = "okay";
                        xlnx,ip-name = "psv_coresight_fpd_cti1c";
                        reg = <0x0 0xf0bc0000 0x0 0x10000>;
                };

                CIPS_0_pspmc_0_psv_coresight_fpd_cti1d: CIPS_0_pspmc_0_psv_coresight_fpd_cti1d@f0bd0000 {
                        phandle = <0x19>;
                        compatible = "xlnx,psv-coresight-fpd-cti1d-1.0";
                        status = "okay";
                        xlnx,ip-name = "psv_coresight_fpd_cti1d";
                        reg = <0x0 0xf0bd0000 0x0 0x10000>;
                };

                CIPS_0_pspmc_0_psv_coresight_lpd_cti: CIPS_0_pspmc_0_psv_coresight_lpd_cti@f09d0000 {
                        phandle = <0x12>;
                        compatible = "xlnx,psv-coresight-lpd-cti-1.0";
                        status = "okay";
                        xlnx,ip-name = "psv_coresight_lpd_cti";
                        reg = <0x0 0xf09d0000 0x0 0x10000>;
                };

                CIPS_0_pspmc_0_psv_coresight_pmc_cti: CIPS_0_pspmc_0_psv_coresight_pmc_cti@f08d0000 {
                        phandle = <0x10>;
                        compatible = "xlnx,psv-coresight-pmc-cti-1.0";
                        status = "okay";
                        xlnx,ip-name = "psv_coresight_pmc_cti";
                        reg = <0x0 0xf08d0000 0x0 0x10000>;
                };

                CIPS_0_pspmc_0_psv_coresight_r50_cti: CIPS_0_pspmc_0_psv_coresight_r50_cti@f0a10000 {
                        phandle = <0x13>;
                        compatible = "xlnx,psv-coresight-r50-cti-1.0";
                        status = "okay";
                        xlnx,ip-name = "psv_coresight_r50_cti";
                        reg = <0x0 0xf0a10000 0x0 0x10000>;
                };

                CIPS_0_pspmc_0_psv_coresight_r51_cti: CIPS_0_pspmc_0_psv_coresight_r51_cti@f0a50000 {
                        phandle = <0x14>;
                        compatible = "xlnx,psv-coresight-r51-cti-1.0";
                        status = "okay";
                        xlnx,ip-name = "psv_coresight_r51_cti";
                        reg = <0x0 0xf0a50000 0x0 0x10000>;
                };

                CIPS_0_pspmc_0_psv_cpm: CIPS_0_pspmc_0_psv_cpm@0 {
                        phandle = <0x5c>;
                        compatible = "xlnx,psv-cpm-1.0";
                        status = "okay";
                        xlnx,ip-name = "psv_cpm";
                        reg = <0x0 0xfc000000 0x0 0x1000000>;
                };

                CIPS_0_pspmc_0_psv_pmc_analog_0: CIPS_0_pspmc_0_psv_pmc_analog_0@f1160000 {
                        phandle = <0x36>;
                        compatible = "xlnx,psv-pmc-analog-1.0";
                        status = "okay";
                        xlnx,ip-name = "psv_pmc_analog";
                        reg = <0x0 0xf1160000 0x0 0x30000>;
                        xlnx,npi-scan = <0x0>;
                        xlnx,event-log = <0x0>;
                        xlnx,cram-scan = <0x0>;
                };

                CIPS_0_pspmc_0_psv_pmc_iou_slcr_0: CIPS_0_pspmc_0_psv_pmc_iou_slcr_0@f1060000 {
                        phandle = <0x34>;
                        compatible = "xlnx,psv-pmc-iou-slcr-1.0";
                        status = "okay";
                        xlnx,ip-name = "psv_pmc_iou_slcr";
                        reg = <0x0 0xf1060000 0x0 0x10000>;
                };

                CIPS_0_pspmc_0_psv_pmc_tap: CIPS_0_pspmc_0_psv_pmc_tap@f11a0000 {
                        phandle = <0x37>;
                        compatible = "xlnx,psv-pmc-tap-1.0";
                        status = "okay";
                        xlnx,ip-name = "psv_pmc_tap";
                        reg = <0x0 0xf11a0000 0x0 0x20000>;
                };

                CIPS_0_pspmc_0_psv_xram_atm: CIPS_0_pspmc_0_psv_xram_atm@ff970000 {
                        phandle = <0x80>;
                        compatible = "xlnx,psv-xram-atm-1.0";
                        status = "okay";
                        xlnx,ip-name = "psv_xram_atm";
                        reg = <0x0 0xff970000 0x0 0x10000>;
                };

                CIPS_0_pspmc_0_psv_xram_ctrl_1: CIPS_0_pspmc_0_psv_xram_ctrl_1@ff8e0000 {
                        phandle = <0x75>;
                        compatible = "xlnx,psv-xram-ctrl-1.0";
                        status = "okay";
                        xlnx,ip-name = "psv_xram_ctrl";
                        reg = <0x0 0xff8e0000 0x0 0x10000>;
                };

                CIPS_0_pspmc_0_psv_xram_ctrl_2: CIPS_0_pspmc_0_psv_xram_ctrl_2@ff8f0000 {
                        phandle = <0x76>;
                        compatible = "xlnx,psv-xram-ctrl-1.0";
                        status = "okay";
                        xlnx,ip-name = "psv_xram_ctrl";
                        reg = <0x0 0xff8f0000 0x0 0x10000>;
                };

                CIPS_0_pspmc_0_psv_xram_ctrl_3: CIPS_0_pspmc_0_psv_xram_ctrl_3@ff900000 {
                        phandle = <0x77>;
                        compatible = "xlnx,psv-xram-ctrl-1.0";
                        status = "okay";
                        xlnx,ip-name = "psv_xram_ctrl";
                        reg = <0x0 0xff900000 0x0 0x10000>;
                };

                CIPS_0_pspmc_0_psv_xram_ctrl_4: CIPS_0_pspmc_0_psv_xram_ctrl_4@ff910000 {
                        phandle = <0x78>;
                        compatible = "xlnx,psv-xram-ctrl-1.0";
                        status = "okay";
                        xlnx,ip-name = "psv_xram_ctrl";
                        reg = <0x0 0xff910000 0x0 0x10000>;
                };

                CIPS_0_pspmc_0_psv_xram_global_ctrl: CIPS_0_pspmc_0_psv_xram_global_ctrl@ff950000 {
                        phandle = <0x7e>;
                        compatible = "xlnx,psv-xram-global-ctrl-1.0";
                        status = "okay";
                        xlnx,ip-name = "psv_xram_global_ctrl";
                        reg = <0x0 0xff950000 0x0 0x10000>;
                };

                CIPS_0_pspmc_0_psv_xram_gpv: CIPS_0_pspmc_0_psv_xram_gpv@ff940000 {
                        phandle = <0x7d>;
                        compatible = "xlnx,psv-xram-gpv-1.0";
                        status = "okay";
                        xlnx,ip-name = "psv_xram_gpv";
                        reg = <0x0 0xff940000 0x0 0x10000>;
                };

                CIPS_0_pspmc_0_psv_xram_xmpu_bank_1: CIPS_0_pspmc_0_psv_xram_xmpu_bank_1@ff930000 {
                        phandle = <0x79>;
                        compatible = "xlnx,psv-xram-xmpu-bank-1.0";
                        status = "okay";
                        xlnx,ip-name = "psv_xram_xmpu_bank";
                        reg = <0x0 0xff930000 0x0 0x4000>;
                };

                CIPS_0_pspmc_0_psv_xram_xmpu_bank_2: CIPS_0_pspmc_0_psv_xram_xmpu_bank_2@ff934000 {
                        phandle = <0x7a>;
                        compatible = "xlnx,psv-xram-xmpu-bank-1.0";
                        status = "okay";
                        xlnx,ip-name = "psv_xram_xmpu_bank";
                        reg = <0x0 0xff934000 0x0 0x4000>;
                };

                CIPS_0_pspmc_0_psv_xram_xmpu_bank_3: CIPS_0_pspmc_0_psv_xram_xmpu_bank_3@ff938000 {
                        phandle = <0x7b>;
                        compatible = "xlnx,psv-xram-xmpu-bank-1.0";
                        status = "okay";
                        xlnx,ip-name = "psv_xram_xmpu_bank";
                        reg = <0x0 0xff938000 0x0 0x4000>;
                };

                CIPS_0_pspmc_0_psv_xram_xmpu_bank_4: CIPS_0_pspmc_0_psv_xram_xmpu_bank_4@ff93c000 {
                        phandle = <0x7c>;
                        compatible = "xlnx,psv-xram-xmpu-bank-1.0";
                        status = "okay";
                        xlnx,ip-name = "psv_xram_xmpu_bank";
                        reg = <0x0 0xff93c000 0x0 0x4000>;
                };

                gic: interrupt-controller@f9000000 {
                        phandle = <0x5b>;
                        xlnx,ip-name = "psv_acpu_gic";
                        xlnx,apu-gic-its-ctl = <0xf9020000>;
                        status = "okay";
                        interrupts = <0x1 0x9 0x4>;
                        interrupt-parent = <&gic>;
                        interrupt-controller;
                        reg = <0x0 0xf9000000 0x0 0x80000 0x0 0xf9080000 0x0 0x80000>;
                        ranges;
                        #size-cells = <0x2>;
                        #address-cells = <0x2>;
                        #interrupt-cells = <0x3>;
                        compatible = "arm,gic-v3";

                        gic_its: msi-controller@f9020000 {
                                phandle = <0x4>;
                                reg = <0x0 0xf9020000 0x0 0x20000>;
                                #msi-cells = <0x1>;
                                msi-controller;
                                status = "okay";
                                compatible = "arm,gic-v3-its";
                        };
                };
        };

        amba_xppu: indirect-bus@1 {
                phandle = <0x170>;
                compatible = "indirect-bus";
                #address-cells = <0x2>;
                #size-cells = <0x2>;

                lpd_xppu: xppu@ff990000 {
                        phandle = <0x82>;
                        compatible = "xlnx,xppu";
                        #firewall-cells = <0x0>;
                        reg = <0x0 0xff990000 0x0 0x2000>;
                        status = "okay";
                        xlnx,ip-name = "psv_lpd_xppu";
                };

                pmc_xppu: xppu@f1310000 {
                        phandle = <0x58>;
                        compatible = "xlnx,xppu";
                        #firewall-cells = <0x0>;
                        reg = <0x0 0xf1310000 0x0 0x2000>;
                        status = "okay";
                        xlnx,ip-name = "psv_pmc_xppu";
                };

                pmc_xppu_npi: xppu@f1300000 {
                        phandle = <0x57>;
                        compatible = "xlnx,xppu";
                        #firewall-cells = <0x0>;
                        reg = <0x0 0xf1300000 0x0 0x2000>;
                        status = "okay";
                        xlnx,ip-name = "psv_pmc_xppu_npi";
                };
        };

        amba_xmpu: indirect-bus@2 {
                phandle = <0x171>;
                compatible = "indirect-bus";
                #address-cells = <0x2>;
                #size-cells = <0x2>;

                fpd_xmpu: xmpu@fd390000 {
                        phandle = <0x61>;
                        compatible = "xlnx,xmpu";
                        #firewall-cells = <0x0>;
                        reg = <0x0 0xfd390000 0x0 0x1000>;
                        status = "okay";
                        xlnx,ip-name = "psv_fpd_slave_xmpu";
                };

                pmc_xmpu: xmpu@f12f0000 {
                        phandle = <0x56>;
                        compatible = "xlnx,xmpu";
                        #firewall-cells = <0x0>;
                        reg = <0x0 0xf12f0000 0x0 0x1000>;
                        status = "okay";
                        xlnx,ip-name = "psv_pmc_xmpu";
                };

                ocm_xmpu: xmpu@ff980000 {
                        phandle = <0x81>;
                        compatible = "xlnx,xmpu";
                        #firewall-cells = <0x0>;
                        reg = <0x0 0xff980000 0x0 0x1000>;
                        status = "okay";
                        xlnx,ip-name = "psv_ocm_xmpu";
                };

                ddrmc_xmpu_0: xmpu@f6080000 {
                        phandle = <0x172>;
                        compatible = "xlnx,xmpu";
                        #firewall-cells = <0x0>;
                        reg = <0x0 0xf6080000 0x0 0x1000>;
                        status = "disabled";
                };

                ddrmc_xmpu_1: xmpu@f6220000 {
                        phandle = <0x173>;
                        compatible = "xlnx,xmpu";
                        #firewall-cells = <0x0>;
                        reg = <0x0 0xf6220000 0x0 0x1000>;
                        status = "disabled";
                };

                ddrmc_xmpu_2: xmpu@f6390000 {
                        phandle = <0x174>;
                        compatible = "xlnx,xmpu";
                        #firewall-cells = <0x0>;
                        reg = <0x0 0xf6390000 0x0 0x1000>;
                        status = "disabled";
                };

                ddrmc_xmpu_3: xmpu@f6500000 {
                        phandle = <0x175>;
                        compatible = "xlnx,xmpu";
                        #firewall-cells = <0x0>;
                        reg = <0x0 0xf6500000 0x0 0x1000>;
                        status = "disabled";
                };
        };

        pl_alt_ref: pl-alt-ref {
                phandle = <0xb5>;
                bootph-all;
                compatible = "fixed-clock";
                #clock-cells = <0x0>;
                clock-frequency = <0x1fca055>;
                clock-output-names = "pl_alt_ref_clk";
        };

        ref: ref {
                phandle = <0xb4>;
                bootph-all;
                compatible = "fixed-clock";
                #clock-cells = <0x0>;
                clock-frequency = <0x1fca055>;
                clock-output-names = "ref_clk";
        };

        can0_clk: can0-clk {
                phandle = <0xaf>;
                #clock-cells = <0x0>;
                compatible = "fixed-factor-clock";
                clocks = <&versal_clk 0x60>;
                clock-div = <0x2>;
                clock-mult = <0x1>;
                clock-output-names = "can0_clk";
        };

        can1_clk: can1-clk {
                phandle = <0xb0>;
                #clock-cells = <0x0>;
                compatible = "fixed-factor-clock";
                clocks = <&versal_clk 0x61>;
                clock-div = <0x2>;
                clock-mult = <0x1>;
                clock-output-names = "can1_clk";
        };

        firmware {

                versal_firmware: versal-firmware {
                        phandle = <0x95>;
                        compatible = "xlnx,versal-firmware";
                        interrupt-parent = <&gic>;
                        bootph-all;
                        method = "smc";
                        #power-domain-cells = <0x1>;

                        versal_clk: clock-controller {
                                phandle = <0x97>;
                                bootph-all;
                                #clock-cells = <0x1>;
                                compatible = "xlnx,versal-clk";
                                clocks = <&ref>,
                                 <&pl_alt_ref>;
                                clock-names = "ref", "pl_alt_ref";
                        };

                        zynqmp_power: power-management {
                                phandle = <0x176>;
                                compatible = "xlnx,zynqmp-power";
                        };

                        versal_reset: reset-controller {
                                phandle = <0xb1>;
                                compatible = "xlnx,versal-reset";
                                #reset-cells = <0x1>;
                        };

                        pinctrl0: pinctrl {
                                phandle = <0x177>;
                                compatible = "xlnx,versal-pinctrl";
                        };

                        versal_sec_cfg: versal-sec-cfg {
                                phandle = <0x178>;
                                compatible = "xlnx,versal-sec-cfg";

                                nvmem-layout {
                                        compatible = "fixed-layout";
                                        #address-cells = <0x1>;
                                        #size-cells = <0x1>;

                                        bbram_zeroize: bbram-zeroize@4 {
                                                phandle = <0x179>;
                                                reg = <0x4 0x4>;
                                        };

                                        bbram_key: bbram-key@10 {
                                                phandle = <0x17a>;
                                                reg = <0x10 0x20>;
                                        };

                                        bbram_usr: bbram-usr@30 {
                                                phandle = <0x17b>;
                                                reg = <0x30 0x4>;
                                        };

                                        bbram_lock: bbram-lock@48 {
                                                phandle = <0x17c>;
                                                reg = <0x48 0x4>;
                                        };

                                        user_key0: user-key@110 {
                                                phandle = <0x17d>;
                                                reg = <0x110 0x20>;
                                        };

                                        user_key1: user-key@130 {
                                                phandle = <0x17e>;
                                                reg = <0x130 0x20>;
                                        };

                                        user_key2: user-key@150 {
                                                phandle = <0x17f>;
                                                reg = <0x150 0x20>;
                                        };

                                        user_key3: user-key@170 {
                                                phandle = <0x180>;
                                                reg = <0x170 0x20>;
                                        };

                                        user_key4: user-key@190 {
                                                phandle = <0x181>;
                                                reg = <0x190 0x20>;
                                        };

                                        user_key5: user-key@1b0 {
                                                phandle = <0x182>;
                                                reg = <0x1b0 0x20>;
                                        };

                                        user_key6: user-key@1d0 {
                                                phandle = <0x183>;
                                                reg = <0x1d0 0x20>;
                                        };

                                        user_key7: user-key@1f0 {
                                                phandle = <0x184>;
                                                reg = <0x1f0 0x20>;
                                        };
                                };
                        };
                };
        };

        amba_pl: amba_pl {
                phandle = <0x185>;
                ranges;
                compatible = "simple-bus";
                #address-cells = <0x2>;
                #size-cells = <0x2>;
                firmware-name = "";

                axi_intc_0: interrupt-controller@a4000000 {
                        phandle = <0xd>;
                        #interrupt-cells = <0x2>;
                        interrupts = <0x0 0x54 0x4>;
                        xlnx,sense-of-irq-edge-type = "Rising";
                        xlnx,edk-special = "INTR_CTRL";
                        xlnx,kind-of-intr = <0x1>;
                        xlnx,kind-of-edge = <0xffffffff>;
                        xlnx,irq-is-level = <0x1>;
                        xlnx,has-ivr = <0x1>;
                        compatible = "xlnx,axi-intc-4.1", "xlnx,xps-intc-1.00.a";
                        xlnx,disable-synchronizers = <0x0>;
                        xlnx,kind-of-lvl = <0xffffffff>;
                        xlnx,ivar-reset-value = <0x10>;
                        xlnx,irq-active = <0x1>;
                        interrupt-parent = <&gic>;
                        xlnx,en-cascade-mode = <0x0>;
                        xlnx,ip-name = "axi_intc";
                        xlnx,has-ilr = <0x0>;
                        reg = <0x0 0xa4000000 0x0 0x10000>;
                        xlnx,addr-width = <0x20>;
                        clocks = <&misc_clk_0>;
                        xlnx,s-axi-aclk-freq-mhz = <0xee6b417>;
                        xlnx,num-sw-intr = <0x0>;
                        xlnx,irq-connection = <0x1>;
                        xlnx,num-intr-inputs = <0x20>;
                        xlnx,has-sie = <0x1>;
                        xlnx,enable-async = <0x0>;
                        xlnx,has-cie = <0x1>;
                        xlnx,num-sync-ff = <0x2>;
                        xlnx,edk-iptype = "PERIPHERAL";
                        xlnx,mb-clk-not-connected = <0x1>;
                        xlnx,has-ipr = <0x1>;
                        xlnx,sense-of-irq-level-type = "Active_High";
                        xlnx,cascade-master = <0x0>;
                        xlnx,processor-clk-freq-mhz = <0x64>;
                        status = "okay";
                        xlnx,is-fast = <0x0>;
                        clock-names = "s_axi_aclk";
                        xlnx,has-fast = <0x0>;
                        xlnx,ivar-rst-val = <0x10>;
                        interrupt-controller;
                        interrupt-names = "irq";
                        xlnx,async-intr = <0xffffffff>;
                };

                ai_engine_0: ai_engine@20000000000 {
                        phandle = <0x92>;
                        xlnx,num-mi-axi = <0x0>;
                        compatible = "xlnx,ai-engine-2.0", "xlnx,ai-engine-v2.0";
                        xlnx,aie-ref-clk-freqmhz = <0x1fc9f08>;
                        xlnx,aie-col-dict = "col00 0x20000000000 col01 0x20002000000 col02 0x20004000000 col03 0x20006000000 col04 0x20008000000 col05 0x2000A000000 col06 0x2000C000000 col07 0x2000E000000 col08 0x20010000000 col09 0x20012000000 col10 0x20014000000 col11 0x20016000000 col12 0x20018000000 col13 0x2001A000000 col14 0x2001C000000 col15 0x2001E000000 col16 0x20020000000";
                        xlnx,num-mi-axis = <0x0>;
                        xlnx,aie-max-freq = <0x3e8>;
                        xlnx,en-addr-virtualization = <0x0>;
                        xlnx,aie-gen = [02];
                        xlnx,mem-rows = /bits/ 8 <0x01 0x01>;
                        xlnx,mi-destid-pins;
                        xlnx,ip-name = "ai_engine";
                        #size-cells = <0x2>;
                        xlnx,num-si-axi = <0x1>;
                        xlnx,fast-pm-write;
                        reg = <0x200 0x0 0x1 0x0>;
                        clocks = <&aie_core_ref_clk_0>;
                        xlnx,num-noc-axis-clks = <0x0>;
                        ranges;
                        xlnx,num-clks = <0x0>;
                        xlnx,partition-enabled = <0x0>;
                        #address-cells = <0x2>;
                        xlnx,num-si-axis = <0x0>;
                        xlnx,num-column = <0x1>;
                        xlnx,aie-core-ref-ctrl-freqmhz = <0x3e8>;
                        xlnx,fast-dm-write;
                        xlnx,edk-iptype = "PERIPHERAL";
                        xlnx,selected-nsu = <0x0>;
                        xlnx,available-nsu = "NOC_NSU128_X1Y6 0x20000000000 NOC_NSU128_X2Y6 0x20002000000 NOC_NSU128_X3Y6 0x20008000000 NOC_NSU128_X4Y6 0x2000C000000 NOC_NSU128_X5Y6 0x2000E000000 NOC_NSU128_X6Y6 0x20014000000";
                        status = "okay";
                        clock-names = "aclk0";
                        power-domains = <&versal_firmware 0x18800000>;
                        xlnx,num-trig-in = <0x0>;
                        xlnx,nsu-dict = "NOC_NSU128_X1Y6 0x20000000000 NOC_NSU128_X2Y6 0x20002000000 NOC_NSU128_X3Y6 0x20008000000 NOC_NSU128_X4Y6 0x2000C000000 NOC_NSU128_X5Y6 0x2000E000000 NOC_NSU128_X6Y6 0x20014000000";
                        xlnx,en-ext-rst = <0x0>;
                        xlnx,num-trig-out = <0x0>;
                        xlnx,core-rows = /bits/ 8 <0x02 0x02>;
                        xlnx,shim-rows = /bits/ 8 <0x00 0x01>;
                        xlnx,name-si-axi = "S00_AXI,";
                        xlnx,start-column = <0x0>;
                        xlnx,aie-site = "AIE_ML";

                        aie_aperture_0: aie_aperture@20000000000 {
                                phandle = <0x186>;
                                xlnx,device-name = <0x0>;
                                interrupt-parent = <&gic>;
                                interrupts = <0x0 0x94 0x4 0x0 0x95 0x4 0x0 0x96 0x4>;
                                #address-cells = <0x2>;
                                power-domains = <&versal_firmware 0x18800000>;
                                xlnx,node-id = <0x18800000>;
                                #size-cells = <0x2>;
                                interrupt-names = "interrupt1", "interrupt2", "interrupt3";
                                reg = <0x200 0x0 0x1 0x0>;
                                xlnx,columns = <0x0 0x11>;
                        };
                };
        };

        noc_ddr4_ddr_memory: memory@00000000 {
                phandle = <0x3>;
                compatible = "xlnx,axi-noc-1.1";
                xlnx,ip-name = "axi_noc";
                device_type = "memory";
                reg = <0x0 0x0 0x0 0x80000000 0x8 0x0 0x1 0x80000000>;
                memory_type = "memory";
        };

        chosen {
                stdout-path = "serial0:115200n8";
        };

        aliases {
                serial0 = "/axi/serial@ff010000";
                serial1 = "/axi/coresight@f0800000";
                i2c0 = "/axi/i2c@ff030000";
                ethernet0 = "/axi/ethernet@ff0c0000";
        };

        __symbols__ {
                cpus_a72 = "/cpus-a72@0";
                psv_cortexa72_0 = "/cpus-a72@0/cpu@0";
                psv_cortexa72_1 = "/cpus-a72@0/cpu@1";
                CPU_SLEEP_0 = "/cpus-a72@0/idle-states/cpu-sleep-0";
                l2 = "/l2-cache";
                cpu_opp_table = "/opp-table-cpu";
                dcc = "/dcc";
                fpga = "/fpga-region";
                psci = "/psci";
                timer = "/timer";
                versal_fpga = "/versal-fpga";
                sensor0 = "/versal-thermal-sensor";
                versal_thermal = "/thermal-zones/versal-thermal";
                temp_alert = "/thermal-zones/versal-thermal/trips/temp-alert";
                ot_crit = "/thermal-zones/versal-thermal/trips/ot-crit";
                versal_thermal_aie = "/thermal-zones/versal-aie-thermal";
                temp_alert_aie = "/thermal-zones/versal-aie-thermal/trips/temp-alert-aie";
                ot_crit_aie = "/thermal-zones/versal-aie-thermal/trips/ot-crit-aie";
                amba_apu = "/apu-bus";
                gic_its = "/axi/interrupt-controller@f9000000/msi-controller@f9020000";
                amba = "/axi";
                imux = "/axi/interrupt-multiplex";
                can0 = "/axi/can@ff060000";
                can1 = "/axi/can@ff070000";
                cci = "/axi/cci@fd000000";
                cci_pmu = "/axi/cci@fd000000/pmu@10000";
                lpd_dma_chan0 = "/axi/dma-controller@ffa80000";
                lpd_dma_chan1 = "/axi/dma-controller@ffa90000";
                lpd_dma_chan2 = "/axi/dma-controller@ffaa0000";
                lpd_dma_chan3 = "/axi/dma-controller@ffab0000";
                lpd_dma_chan4 = "/axi/dma-controller@ffac0000";
                lpd_dma_chan5 = "/axi/dma-controller@ffad0000";
                lpd_dma_chan6 = "/axi/dma-controller@ffae0000";
                lpd_dma_chan7 = "/axi/dma-controller@ffaf0000";
                gem0 = "/axi/ethernet@ff0c0000";
                gem1 = "/axi/ethernet@ff0d0000";
                gpio0 = "/axi/gpio@ff0b0000";
                gpio1 = "/axi/gpio@f1020000";
                i2c0 = "/axi/i2c@ff020000";
                i2c_cruvi_hs1 = "/axi/i2c@ff020000/i2cswitch@70/i2c@0";
                i2c_cruvi_hs2 = "/axi/i2c@ff020000/i2cswitch@70/i2c@1";
                i2c_qsfp = "/axi/i2c@ff020000/i2cswitch@70/i2c@2";
                i2c_fmc = "/axi/i2c@ff020000/i2cswitch@70/i2c@3";
                i2c1 = "/axi/i2c@ff030000";
                i2c2 = "/axi/i2c@f1000000";
                eeprom = "/axi/i2c@f1000000/eeprom@50";
                eth0_addr = "/axi/i2c@f1000000/eeprom@50/eth-mac-addr@FA";
                mc0 = "/axi/memory-controller@f6150000";
                mc1 = "/axi/memory-controller@f62c0000";
                mc2 = "/axi/memory-controller@f6430000";
                mc3 = "/axi/memory-controller@f65a0000";
                ocm = "/axi/memory-controller@ff960000";
                rtc = "/axi/rtc@f12a0000";
                sdhci0 = "/axi/mmc@f1040000";
                sdhci1 = "/axi/mmc@f1050000";
                serial0 = "/axi/serial@ff000000";
                serial1 = "/axi/serial@ff010000";
                smmu = "/axi/iommu@fd800000";
                ospi = "/axi/spi@f1010000";
                qspi = "/axi/spi@f1030000";
                spi0 = "/axi/spi@ff040000";
                spi1 = "/axi/spi@ff050000";
                sysmon0 = "/axi/sysmon@f1270000";
                sysmon1 = "/axi/sysmon@109270000";
                sysmon2 = "/axi/sysmon@111270000";
                sysmon3 = "/axi/sysmon@119270000";
                ttc0 = "/axi/timer@ff0e0000";
                ttc1 = "/axi/timer@ff0f0000";
                ttc2 = "/axi/timer@ff100000";
                ttc3 = "/axi/timer@ff110000";
                usb0 = "/axi/usb@ff9d0000";
                dwc3_0 = "/axi/usb@ff9d0000/usb@fe200000";
                cpm_pciea = "/axi/pci@fca10000";
                pcie_intc_0 = "/axi/pci@fca10000/interrupt-controller";
                cpm5_pcie = "/axi/pcie@fcdd0000";
                pcie_intc_2 = "/axi/pcie@fcdd0000/interrupt-controller";
                watchdog = "/axi/watchdog@fd4d0000";
                watchdog1 = "/axi/watchdog@ff120000";
                xilsem_edac = "/axi/edac@f2014050";
                dma0 = "/axi/pmcdma@f11c0000";
                dma1 = "/axi/pmcdma@f11d0000";
                ipi0 = "/axi/mailbox@ff330000";
                ipi_0_to_ipi_0 = "/axi/mailbox@ff330000/child@ff330000";
                ipi_0_to_ipi_1 = "/axi/mailbox@ff330000/child@ff340000";
                ipi_0_to_ipi_2 = "/axi/mailbox@ff330000/child@ff350000";
                ipi_0_to_ipi_3 = "/axi/mailbox@ff330000/child@ff360000";
                ipi_0_to_ipi_4 = "/axi/mailbox@ff330000/child@ff370000";
                ipi_0_to_ipi_5 = "/axi/mailbox@ff330000/child@ff380000";
                ipi_0_to_ipi_6 = "/axi/mailbox@ff330000/child@ff3a0000";
                ipi_0_to_ipi_pmc = "/axi/mailbox@ff330000/child@ff320000";
                ipi_0_to_ipi_pmc_nobuf = "/axi/mailbox@ff330000/child@ff390000";
                ipi_0_to_ipi_psm = "/axi/mailbox@ff330000/child@ff310000";
                ipi1 = "/axi/mailbox@ff340000";
                ipi_1_to_ipi_0 = "/axi/mailbox@ff340000/child@ff330000";
                ipi_1_to_ipi_1 = "/axi/mailbox@ff340000/child@ff340000";
                ipi_1_to_ipi_2 = "/axi/mailbox@ff340000/child@ff350000";
                ipi_1_to_ipi_3 = "/axi/mailbox@ff340000/child@ff360000";
                ipi_1_to_ipi_4 = "/axi/mailbox@ff340000/child@ff370000";
                ipi_1_to_ipi_5 = "/axi/mailbox@ff340000/child@ff380000";
                ipi_1_to_ipi_6 = "/axi/mailbox@ff340000/child@ff3a0000";
                ipi_1_to_ipi_pmc = "/axi/mailbox@ff340000/child@ff320000";
                ipi_1_to_ipi_pmc_nobuf = "/axi/mailbox@ff340000/child@ff390000";
                ipi_1_to_ipi_psm = "/axi/mailbox@ff340000/child@ff310000";
                ipi2 = "/axi/mailbox@ff350000";
                ipi_2_to_ipi_0 = "/axi/mailbox@ff350000/child@ff330000";
                ipi_2_to_ipi_1 = "/axi/mailbox@ff350000/child@ff340000";
                ipi_2_to_ipi_2 = "/axi/mailbox@ff350000/child@ff350000";
                ipi_2_to_ipi_3 = "/axi/mailbox@ff350000/child@ff360000";
                ipi_2_to_ipi_4 = "/axi/mailbox@ff350000/child@ff370000";
                ipi_2_to_ipi_5 = "/axi/mailbox@ff350000/child@ff380000";
                ipi_2_to_ipi_6 = "/axi/mailbox@ff350000/child@ff3a0000";
                ipi_2_to_ipi_pmc = "/axi/mailbox@ff350000/child@ff320000";
                ipi_2_to_ipi_pmc_nobuf = "/axi/mailbox@ff350000/child@ff390000";
                ipi_2_to_ipi_psm = "/axi/mailbox@ff350000/child@ff310000";
                ipi3 = "/axi/mailbox@ff360000";
                ipi_3_to_ipi_0 = "/axi/mailbox@ff360000/child@ff330000";
                ipi_3_to_ipi_1 = "/axi/mailbox@ff360000/child@ff340000";
                ipi_3_to_ipi_2 = "/axi/mailbox@ff360000/child@ff350000";
                ipi_3_to_ipi_3 = "/axi/mailbox@ff360000/child@ff360000";
                ipi_3_to_ipi_4 = "/axi/mailbox@ff360000/child@ff370000";
                ipi_3_to_ipi_5 = "/axi/mailbox@ff360000/child@ff380000";
                ipi_3_to_ipi_6 = "/axi/mailbox@ff360000/child@ff3a0000";
                ipi_3_to_ipi_pmc = "/axi/mailbox@ff360000/child@ff320000";
                ipi_3_to_ipi_pmc_nobuf = "/axi/mailbox@ff360000/child@ff390000";
                ipi_3_to_ipi_psm = "/axi/mailbox@ff360000/child@ff310000";
                ipi4 = "/axi/mailbox@ff370000";
                ipi_4_to_ipi_0 = "/axi/mailbox@ff370000/child@ff330000";
                ipi_4_to_ipi_1 = "/axi/mailbox@ff370000/child@ff340000";
                ipi_4_to_ipi_2 = "/axi/mailbox@ff370000/child@ff350000";
                ipi_4_to_ipi_3 = "/axi/mailbox@ff370000/child@ff360000";
                ipi_4_to_ipi_4 = "/axi/mailbox@ff370000/child@ff370000";
                ipi_4_to_ipi_5 = "/axi/mailbox@ff370000/child@ff380000";
                ipi_4_to_ipi_6 = "/axi/mailbox@ff370000/child@ff3a0000";
                ipi_4_to_ipi_pmc = "/axi/mailbox@ff370000/child@ff320000";
                ipi_4_to_ipi_pmc_nobuf = "/axi/mailbox@ff370000/child@ff390000";
                ipi_4_to_ipi_psm = "/axi/mailbox@ff370000/child@ff310000";
                ipi5 = "/axi/mailbox@ff380000";
                ipi_5_to_ipi_0 = "/axi/mailbox@ff380000/child@ff330000";
                ipi_5_to_ipi_1 = "/axi/mailbox@ff380000/child@ff340000";
                ipi_5_to_ipi_2 = "/axi/mailbox@ff380000/child@ff350000";
                ipi_5_to_ipi_3 = "/axi/mailbox@ff380000/child@ff360000";
                ipi_5_to_ipi_4 = "/axi/mailbox@ff380000/child@ff370000";
                ipi_5_to_ipi_5 = "/axi/mailbox@ff380000/child@ff380000";
                ipi_5_to_ipi_6 = "/axi/mailbox@ff380000/child@ff3a0000";
                ipi_5_to_ipi_pmc = "/axi/mailbox@ff380000/child@ff320000";
                ipi_5_to_ipi_pmc_nobuf = "/axi/mailbox@ff380000/child@ff390000";
                ipi_5_to_ipi_psm = "/axi/mailbox@ff380000/child@ff310000";
                ipi6 = "/axi/mailbox@ff3a0000";
                ipi_6_to_ipi_0 = "/axi/mailbox@ff3a0000/child@ff330000";
                ipi_6_to_ipi_1 = "/axi/mailbox@ff3a0000/child@ff340000";
                ipi_6_to_ipi_2 = "/axi/mailbox@ff3a0000/child@ff350000";
                ipi_6_to_ipi_3 = "/axi/mailbox@ff3a0000/child@ff360000";
                ipi_6_to_ipi_4 = "/axi/mailbox@ff3a0000/child@ff370000";
                ipi_6_to_ipi_5 = "/axi/mailbox@ff3a0000/child@ff380000";
                ipi_6_to_ipi_6 = "/axi/mailbox@ff3a0000/child@ff3a0000";
                ipi_6_to_ipi_pmc = "/axi/mailbox@ff3a0000/child@ff320000";
                ipi_6_to_ipi_pmc_nobuf = "/axi/mailbox@ff3a0000/child@ff390000";
                ipi_6_to_ipi_psm = "/axi/mailbox@ff3a0000/child@ff310000";
                coresight = "/axi/coresight@f0800000";
                CIPS_0_pspmc_0_psv_coresight_fpd_cti1b = "/axi/CIPS_0_pspmc_0_psv_coresight_fpd_cti1b@f0bb0000";
                CIPS_0_pspmc_0_psv_coresight_fpd_cti1c = "/axi/CIPS_0_pspmc_0_psv_coresight_fpd_cti1c@f0bc0000";
                CIPS_0_pspmc_0_psv_coresight_fpd_cti1d = "/axi/CIPS_0_pspmc_0_psv_coresight_fpd_cti1d@f0bd0000";
                CIPS_0_pspmc_0_psv_coresight_lpd_cti = "/axi/CIPS_0_pspmc_0_psv_coresight_lpd_cti@f09d0000";
                CIPS_0_pspmc_0_psv_coresight_pmc_cti = "/axi/CIPS_0_pspmc_0_psv_coresight_pmc_cti@f08d0000";
                CIPS_0_pspmc_0_psv_coresight_r50_cti = "/axi/CIPS_0_pspmc_0_psv_coresight_r50_cti@f0a10000";
                CIPS_0_pspmc_0_psv_coresight_r51_cti = "/axi/CIPS_0_pspmc_0_psv_coresight_r51_cti@f0a50000";
                CIPS_0_pspmc_0_psv_cpm = "/axi/CIPS_0_pspmc_0_psv_cpm@0";
                CIPS_0_pspmc_0_psv_pmc_analog_0 = "/axi/CIPS_0_pspmc_0_psv_pmc_analog_0@f1160000";
                CIPS_0_pspmc_0_psv_pmc_iou_slcr_0 = "/axi/CIPS_0_pspmc_0_psv_pmc_iou_slcr_0@f1060000";
                CIPS_0_pspmc_0_psv_pmc_tap = "/axi/CIPS_0_pspmc_0_psv_pmc_tap@f11a0000";
                CIPS_0_pspmc_0_psv_xram_atm = "/axi/CIPS_0_pspmc_0_psv_xram_atm@ff970000";
                CIPS_0_pspmc_0_psv_xram_ctrl_1 = "/axi/CIPS_0_pspmc_0_psv_xram_ctrl_1@ff8e0000";
                CIPS_0_pspmc_0_psv_xram_ctrl_2 = "/axi/CIPS_0_pspmc_0_psv_xram_ctrl_2@ff8f0000";
                CIPS_0_pspmc_0_psv_xram_ctrl_3 = "/axi/CIPS_0_pspmc_0_psv_xram_ctrl_3@ff900000";
                CIPS_0_pspmc_0_psv_xram_ctrl_4 = "/axi/CIPS_0_pspmc_0_psv_xram_ctrl_4@ff910000";
                CIPS_0_pspmc_0_psv_xram_global_ctrl = "/axi/CIPS_0_pspmc_0_psv_xram_global_ctrl@ff950000";
                CIPS_0_pspmc_0_psv_xram_gpv = "/axi/CIPS_0_pspmc_0_psv_xram_gpv@ff940000";
                CIPS_0_pspmc_0_psv_xram_xmpu_bank_1 = "/axi/CIPS_0_pspmc_0_psv_xram_xmpu_bank_1@ff930000";
                CIPS_0_pspmc_0_psv_xram_xmpu_bank_2 = "/axi/CIPS_0_pspmc_0_psv_xram_xmpu_bank_2@ff934000";
                CIPS_0_pspmc_0_psv_xram_xmpu_bank_3 = "/axi/CIPS_0_pspmc_0_psv_xram_xmpu_bank_3@ff938000";
                CIPS_0_pspmc_0_psv_xram_xmpu_bank_4 = "/axi/CIPS_0_pspmc_0_psv_xram_xmpu_bank_4@ff93c000";
                amba_xppu = "/indirect-bus@1";
                lpd_xppu = "/indirect-bus@1/xppu@ff990000";
                pmc_xppu = "/indirect-bus@1/xppu@f1310000";
                pmc_xppu_npi = "/indirect-bus@1/xppu@f1300000";
                amba_xmpu = "/indirect-bus@2";
                fpd_xmpu = "/indirect-bus@2/xmpu@fd390000";
                pmc_xmpu = "/indirect-bus@2/xmpu@f12f0000";
                ocm_xmpu = "/indirect-bus@2/xmpu@ff980000";
                ddrmc_xmpu_0 = "/indirect-bus@2/xmpu@f6080000";
                ddrmc_xmpu_1 = "/indirect-bus@2/xmpu@f6220000";
                ddrmc_xmpu_2 = "/indirect-bus@2/xmpu@f6390000";
                ddrmc_xmpu_3 = "/indirect-bus@2/xmpu@f6500000";
                pl_alt_ref = "/pl-alt-ref";
                ref = "/ref";
                can0_clk = "/can0-clk";
                can1_clk = "/can1-clk";
                versal_firmware = "/firmware/versal-firmware";
                versal_clk = "/firmware/versal-firmware/clock-controller";
                zynqmp_power = "/firmware/versal-firmware/power-management";
                versal_reset = "/firmware/versal-firmware/reset-controller";
                pinctrl0 = "/firmware/versal-firmware/pinctrl";
                versal_sec_cfg = "/firmware/versal-firmware/versal-sec-cfg";
                bbram_zeroize = "/firmware/versal-firmware/versal-sec-cfg/nvmem-layout/bbram-zeroize@4";
                bbram_key = "/firmware/versal-firmware/versal-sec-cfg/nvmem-layout/bbram-key@10";
                bbram_usr = "/firmware/versal-firmware/versal-sec-cfg/nvmem-layout/bbram-usr@30";
                bbram_lock = "/firmware/versal-firmware/versal-sec-cfg/nvmem-layout/bbram-lock@48";
                user_key0 = "/firmware/versal-firmware/versal-sec-cfg/nvmem-layout/user-key@110";
                user_key1 = "/firmware/versal-firmware/versal-sec-cfg/nvmem-layout/user-key@130";
                user_key2 = "/firmware/versal-firmware/versal-sec-cfg/nvmem-layout/user-key@150";
                user_key3 = "/firmware/versal-firmware/versal-sec-cfg/nvmem-layout/user-key@170";
                user_key4 = "/firmware/versal-firmware/versal-sec-cfg/nvmem-layout/user-key@190";
                user_key5 = "/firmware/versal-firmware/versal-sec-cfg/nvmem-layout/user-key@1b0";
                user_key6 = "/firmware/versal-firmware/versal-sec-cfg/nvmem-layout/user-key@1d0";
                user_key7 = "/firmware/versal-firmware/versal-sec-cfg/nvmem-layout/user-key@1f0";
                amba_pl = "/amba_pl";
                axi_intc_0 = "/amba_pl/interrupt-controller@a4000000";
                ai_engine_0 = "/amba_pl/ai_engine@20000000000";
                aie_aperture_0 = "/amba_pl/ai_engine@20000000000/aie_aperture@20000000000";
                noc_ddr4_ddr_memory = "/memory@00000000";
                gic = "/axi/interrupt-controller@f9000000";
        };

        misc_clk_0: misc_clk_0 {
                phandle = <0xb6>;
                compatible = "fixed-clock";
                clock-frequency = <0xee6b417>;
                #clock-cells = <0x0>;
        };

        aie_core_ref_clk_0: aie_core_ref_clk_0 {
                phandle = <0xb7>;
                compatible = "fixed-clock";
                clock-frequency = <0x3b9aca00>;
                #clock-cells = <0x0>;
        };

        zyxclmm_drm {
                compatible = "xlnx,zocl-versal";
                interrupts-extended = <&axi_intc_0 0x0 0x4>,
                 <&axi_intc_0 0x1 0x4>,
                 <&axi_intc_0 0x2 0x4>,
                 <&axi_intc_0 0x3 0x4>,
                 <&axi_intc_0 0x4 0x4>,
                 <&axi_intc_0 0x5 0x4>,
                 <&axi_intc_0 0x6 0x4>,
                 <&axi_intc_0 0x7 0x4>,
                 <&axi_intc_0 0x8 0x4>,
                 <&axi_intc_0 0x9 0x4>,
                 <&axi_intc_0 0xa 0x4>,
                 <&axi_intc_0 0xb 0x4>,
                 <&axi_intc_0 0xc 0x4>,
                 <&axi_intc_0 0xd 0x4>,
                 <&axi_intc_0 0xe 0x4>,
                 <&axi_intc_0 0xf 0x4>,
                 <&axi_intc_0 0x10 0x4>,
                 <&axi_intc_0 0x11 0x4>,
                 <&axi_intc_0 0x12 0x4>,
                 <&axi_intc_0 0x13 0x4>,
                 <&axi_intc_0 0x14 0x4>,
                 <&axi_intc_0 0x15 0x4>,
                 <&axi_intc_0 0x16 0x4>,
                 <&axi_intc_0 0x17 0x4>,
                 <&axi_intc_0 0x18 0x4>,
                 <&axi_intc_0 0x19 0x4>,
                 <&axi_intc_0 0x1a 0x4>,
                 <&axi_intc_0 0x1b 0x4>,
                 <&axi_intc_0 0x1c 0x4>,
                 <&axi_intc_0 0x1d 0x4>,
                 <&axi_intc_0 0x1e 0x4>,
                 <&axi_intc_0 0x1f 0x4>;
        };
};
